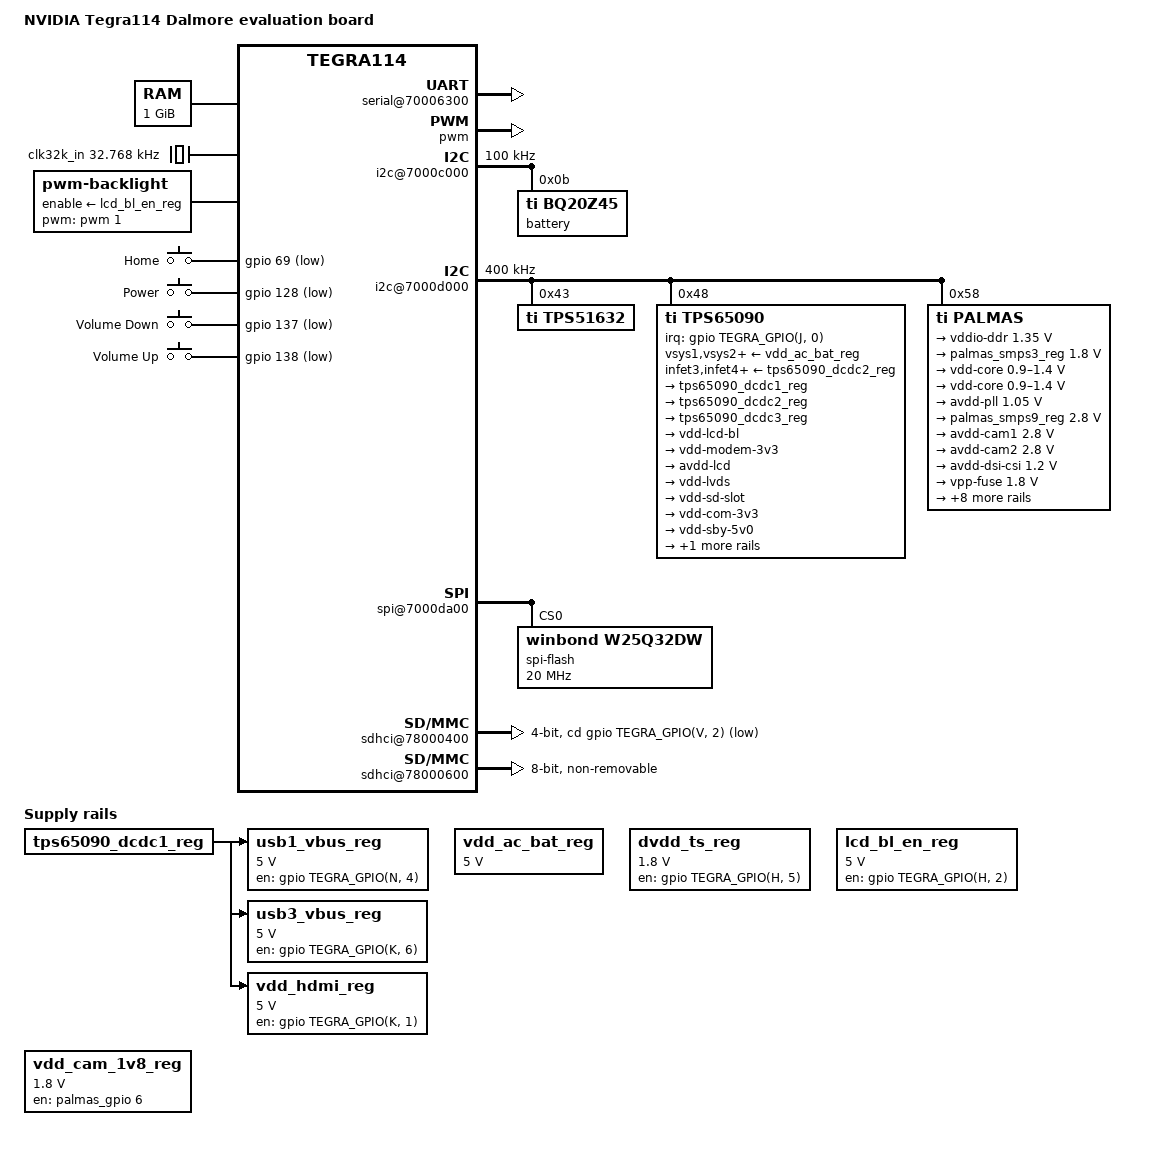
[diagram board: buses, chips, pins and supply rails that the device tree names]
/dts-v1/;

#include "tegra114.dtsi"

/ {
	model = "NVIDIA Tegra114 Dalmore evaluation board";
	compatible = "nvidia,dalmore", "nvidia,tegra114";

	memory {
		reg = <0x80000000 0x40000000>;
	};

	pinmux {
		pinctrl-names = "default";
		pinctrl-0 = <&state_default>;

		state_default: pinmux {
			clk1_out_pw4 {
				nvidia,pins = "clk1_out_pw4";
				nvidia,function = "extperiph1";
				nvidia,pull = <0>;
				nvidia,tristate = <0>;
				nvidia,enable-input = <0>;
			};
			dap1_din_pn1 {
				nvidia,pins = "dap1_din_pn1";
				nvidia,function = "i2s0";
				nvidia,pull = <0>;
				nvidia,tristate = <1>;
				nvidia,enable-input = <1>;
			};
			dap1_dout_pn2 {
				nvidia,pins = "dap1_dout_pn2",
						"dap1_fs_pn0",
						"dap1_sclk_pn3";
				nvidia,function = "i2s0";
				nvidia,pull = <0>;
				nvidia,tristate = <0>;
				nvidia,enable-input = <1>;
			};
			dap2_din_pa4 {
				nvidia,pins = "dap2_din_pa4";
				nvidia,function = "i2s1";
				nvidia,pull = <0>;
				nvidia,tristate = <1>;
				nvidia,enable-input = <1>;
			};
			dap2_dout_pa5 {
				nvidia,pins = "dap2_dout_pa5",
						"dap2_fs_pa2",
						"dap2_sclk_pa3";
				nvidia,function = "i2s1";
				nvidia,pull = <0>;
				nvidia,tristate = <0>;
				nvidia,enable-input = <1>;
			};
			dap4_din_pp5 {
				nvidia,pins = "dap4_din_pp5",
						"dap4_dout_pp6",
						"dap4_fs_pp4",
						"dap4_sclk_pp7";
				nvidia,function = "i2s3";
				nvidia,pull = <0>;
				nvidia,tristate = <0>;
				nvidia,enable-input = <1>;
			};
			dvfs_pwm_px0 {
				nvidia,pins = "dvfs_pwm_px0",
						"dvfs_clk_px2";
				nvidia,function = "cldvfs";
				nvidia,pull = <0>;
				nvidia,tristate = <0>;
				nvidia,enable-input = <0>;
			};
			ulpi_clk_py0 {
				nvidia,pins = "ulpi_clk_py0",
						"ulpi_data0_po1",
						"ulpi_data1_po2",
						"ulpi_data2_po3",
						"ulpi_data3_po4",
						"ulpi_data4_po5",
						"ulpi_data5_po6",
						"ulpi_data6_po7",
						"ulpi_data7_po0";
				nvidia,function = "ulpi";
				nvidia,pull = <0>;
				nvidia,tristate = <0>;
				nvidia,enable-input = <1>;
			};
			ulpi_dir_py1 {
				nvidia,pins = "ulpi_dir_py1",
						"ulpi_nxt_py2";
				nvidia,function = "ulpi";
				nvidia,pull = <0>;
				nvidia,tristate = <1>;
				nvidia,enable-input = <1>;
			};
			ulpi_stp_py3 {
				nvidia,pins = "ulpi_stp_py3";
				nvidia,function = "ulpi";
				nvidia,pull = <0>;
				nvidia,tristate = <0>;
				nvidia,enable-input = <0>;
			};
			cam_i2c_scl_pbb1 {
				nvidia,pins = "cam_i2c_scl_pbb1",
						"cam_i2c_sda_pbb2";
				nvidia,function = "i2c3";
				nvidia,pull = <0>;
				nvidia,tristate = <0>;
				nvidia,enable-input = <1>;
				nvidia,lock = <0>;
				nvidia,open-drain = <0>;
			};
			cam_mclk_pcc0 {
				nvidia,pins = "cam_mclk_pcc0",
						"pbb0";
				nvidia,function = "vi_alt3";
				nvidia,pull = <0>;
				nvidia,tristate = <0>;
				nvidia,enable-input = <0>;
				nvidia,lock = <0>;
			};
			gen2_i2c_scl_pt5 {
				nvidia,pins = "gen2_i2c_scl_pt5",
						"gen2_i2c_sda_pt6";
				nvidia,function = "i2c2";
				nvidia,pull = <0>;
				nvidia,tristate = <0>;
				nvidia,enable-input = <1>;
				nvidia,lock = <0>;
				nvidia,open-drain = <0>;
			};
			gmi_a16_pj7 {
				nvidia,pins = "gmi_a16_pj7";
				nvidia,function = "uartd";
				nvidia,pull = <0>;
				nvidia,tristate = <0>;
				nvidia,enable-input = <0>;
			};
			gmi_a17_pb0 {
				nvidia,pins = "gmi_a17_pb0",
						"gmi_a18_pb1";
				nvidia,function = "uartd";
				nvidia,pull = <0>;
				nvidia,tristate = <1>;
				nvidia,enable-input = <1>;
			};
			gmi_a19_pk7 {
				nvidia,pins = "gmi_a19_pk7";
				nvidia,function = "uartd";
				nvidia,pull = <0>;
				nvidia,tristate = <0>;
				nvidia,enable-input = <0>;
			};
			gmi_ad5_pg5 {
				nvidia,pins = "gmi_ad5_pg5",
						"gmi_cs6_n_pi3",
						"gmi_wr_n_pi0";
				nvidia,function = "spi4";
				nvidia,pull = <0>;
				nvidia,tristate = <0>;
				nvidia,enable-input = <1>;
			};
			gmi_ad6_pg6 {
				nvidia,pins = "gmi_ad6_pg6",
						"gmi_ad7_pg7";
				nvidia,function = "spi4";
				nvidia,pull = <2>;
				nvidia,tristate = <0>;
				nvidia,enable-input = <1>;
			};
			gmi_ad12_ph4 {
				nvidia,pins = "gmi_ad12_ph4";
				nvidia,function = "rsvd4";
				nvidia,pull = <0>;
				nvidia,tristate = <0>;
				nvidia,enable-input = <0>;
			};
			gmi_ad9_ph1 {
				nvidia,pins = "gmi_ad9_ph1";
				nvidia,function = "pwm1";
				nvidia,pull = <0>;
				nvidia,tristate = <0>;
				nvidia,enable-input = <0>;
			};
			gmi_cs1_n_pj2 {
				nvidia,pins = "gmi_cs1_n_pj2",
						"gmi_oe_n_pi1";
				nvidia,function = "soc";
				nvidia,pull = <0>;
				nvidia,tristate = <1>;
				nvidia,enable-input = <1>;
			};
			clk2_out_pw5 {
				nvidia,pins = "clk2_out_pw5";
				nvidia,function = "extperiph2";
				nvidia,pull = <0>;
				nvidia,tristate = <0>;
				nvidia,enable-input = <0>;
			};
			sdmmc1_clk_pz0 {
				nvidia,pins = "sdmmc1_clk_pz0";
				nvidia,function = "sdmmc1";
				nvidia,pull = <0>;
				nvidia,tristate = <0>;
				nvidia,enable-input = <1>;
			};
			sdmmc1_cmd_pz1 {
				nvidia,pins = "sdmmc1_cmd_pz1",
						"sdmmc1_dat0_py7",
						"sdmmc1_dat1_py6",
						"sdmmc1_dat2_py5",
						"sdmmc1_dat3_py4";
				nvidia,function = "sdmmc1";
				nvidia,pull = <2>;
				nvidia,tristate = <0>;
				nvidia,enable-input = <1>;
			};
			sdmmc1_wp_n_pv3 {
				nvidia,pins = "sdmmc1_wp_n_pv3";
				nvidia,function = "spi4";
				nvidia,pull = <2>;
				nvidia,tristate = <0>;
				nvidia,enable-input = <0>;
			};
			sdmmc3_clk_pa6 {
				nvidia,pins = "sdmmc3_clk_pa6";
				nvidia,function = "sdmmc3";
				nvidia,pull = <0>;
				nvidia,tristate = <0>;
				nvidia,enable-input = <1>;
			};
			sdmmc3_cmd_pa7 {
				nvidia,pins = "sdmmc3_cmd_pa7",
						"sdmmc3_dat0_pb7",
						"sdmmc3_dat1_pb6",
						"sdmmc3_dat2_pb5",
						"sdmmc3_dat3_pb4",
						"kb_col4_pq4",
						"sdmmc3_clk_lb_out_pee4",
						"sdmmc3_clk_lb_in_pee5";
				nvidia,function = "sdmmc3";
				nvidia,pull = <2>;
				nvidia,tristate = <0>;
				nvidia,enable-input = <1>;
			};
			sdmmc4_clk_pcc4 {
				nvidia,pins = "sdmmc4_clk_pcc4";
				nvidia,function = "sdmmc4";
				nvidia,pull = <0>;
				nvidia,tristate = <0>;
				nvidia,enable-input = <1>;
			};
			sdmmc4_cmd_pt7 {
				nvidia,pins = "sdmmc4_cmd_pt7",
						"sdmmc4_dat0_paa0",
						"sdmmc4_dat1_paa1",
						"sdmmc4_dat2_paa2",
						"sdmmc4_dat3_paa3",
						"sdmmc4_dat4_paa4",
						"sdmmc4_dat5_paa5",
						"sdmmc4_dat6_paa6",
						"sdmmc4_dat7_paa7";
				nvidia,function = "sdmmc4";
				nvidia,pull = <2>;
				nvidia,tristate = <0>;
				nvidia,enable-input = <1>;
			};
			clk_32k_out_pa0 {
				nvidia,pins = "clk_32k_out_pa0";
				nvidia,function = "blink";
				nvidia,pull = <0>;
				nvidia,tristate = <0>;
				nvidia,enable-input = <0>;
			};
			kb_col0_pq0 {
				nvidia,pins = "kb_col0_pq0",
						"kb_col1_pq1",
						"kb_col2_pq2",
						"kb_row0_pr0",
						"kb_row1_pr1",
						"kb_row2_pr2";
				nvidia,function = "kbc";
				nvidia,pull = <2>;
				nvidia,tristate = <0>;
				nvidia,enable-input = <1>;
			};
			dap3_din_pp1 {
				nvidia,pins = "dap3_din_pp1",
						"dap3_sclk_pp3";
				nvidia,function = "displayb";
				nvidia,pull = <0>;
				nvidia,tristate = <1>;
				nvidia,enable-input = <0>;
			};
			pv0 {
				nvidia,pins = "pv0";
				nvidia,function = "rsvd4";
				nvidia,pull = <0>;
				nvidia,tristate = <1>;
				nvidia,enable-input = <0>;
			};
			kb_row7_pr7 {
				nvidia,pins = "kb_row7_pr7";
				nvidia,function = "rsvd2";
				nvidia,pull = <2>;
				nvidia,tristate = <0>;
				nvidia,enable-input = <1>;
			};
			kb_row10_ps2 {
				nvidia,pins = "kb_row10_ps2";
				nvidia,function = "uarta";
				nvidia,pull = <0>;
				nvidia,tristate = <1>;
				nvidia,enable-input = <1>;
			};
			kb_row9_ps1 {
				nvidia,pins = "kb_row9_ps1";
				nvidia,function = "uarta";
				nvidia,pull = <0>;
				nvidia,tristate = <0>;
				nvidia,enable-input = <0>;
			};
			pwr_i2c_scl_pz6 {
				nvidia,pins = "pwr_i2c_scl_pz6",
						"pwr_i2c_sda_pz7";
				nvidia,function = "i2cpwr";
				nvidia,pull = <0>;
				nvidia,tristate = <0>;
				nvidia,enable-input = <1>;
				nvidia,lock = <0>;
				nvidia,open-drain = <0>;
			};
			sys_clk_req_pz5 {
				nvidia,pins = "sys_clk_req_pz5";
				nvidia,function = "sysclk";
				nvidia,pull = <0>;
				nvidia,tristate = <0>;
				nvidia,enable-input = <0>;
			};
			core_pwr_req {
				nvidia,pins = "core_pwr_req";
				nvidia,function = "pwron";
				nvidia,pull = <0>;
				nvidia,tristate = <0>;
				nvidia,enable-input = <0>;
			};
			cpu_pwr_req {
				nvidia,pins = "cpu_pwr_req";
				nvidia,function = "cpu";
				nvidia,pull = <0>;
				nvidia,tristate = <0>;
				nvidia,enable-input = <0>;
			};
			pwr_int_n {
				nvidia,pins = "pwr_int_n";
				nvidia,function = "pmi";
				nvidia,pull = <0>;
				nvidia,tristate = <1>;
				nvidia,enable-input = <1>;
			};
			reset_out_n {
				nvidia,pins = "reset_out_n";
				nvidia,function = "reset_out_n";
				nvidia,pull = <0>;
				nvidia,tristate = <0>;
				nvidia,enable-input = <0>;
			};
			clk3_out_pee0 {
				nvidia,pins = "clk3_out_pee0";
				nvidia,function = "extperiph3";
				nvidia,pull = <0>;
				nvidia,tristate = <0>;
				nvidia,enable-input = <0>;
			};
			gen1_i2c_scl_pc4 {
				nvidia,pins = "gen1_i2c_scl_pc4",
						"gen1_i2c_sda_pc5";
				nvidia,function = "i2c1";
				nvidia,pull = <0>;
				nvidia,tristate = <0>;
				nvidia,enable-input = <1>;
				nvidia,lock = <0>;
				nvidia,open-drain = <0>;
			};
			uart2_cts_n_pj5 {
				nvidia,pins = "uart2_cts_n_pj5";
				nvidia,function = "uartb";
				nvidia,pull = <0>;
				nvidia,tristate = <1>;
				nvidia,enable-input = <1>;
			};
			uart2_rts_n_pj6 {
				nvidia,pins = "uart2_rts_n_pj6";
				nvidia,function = "uartb";
				nvidia,pull = <0>;
				nvidia,tristate = <0>;
				nvidia,enable-input = <0>;
			};
			uart2_rxd_pc3 {
				nvidia,pins = "uart2_rxd_pc3";
				nvidia,function = "irda";
				nvidia,pull = <0>;
				nvidia,tristate = <1>;
				nvidia,enable-input = <1>;
			};
			uart2_txd_pc2 {
				nvidia,pins = "uart2_txd_pc2";
				nvidia,function = "irda";
				nvidia,pull = <0>;
				nvidia,tristate = <0>;
				nvidia,enable-input = <0>;
			};
			uart3_cts_n_pa1 {
				nvidia,pins = "uart3_cts_n_pa1",
						"uart3_rxd_pw7";
				nvidia,function = "uartc";
				nvidia,pull = <0>;
				nvidia,tristate = <1>;
				nvidia,enable-input = <1>;
			};
			uart3_rts_n_pc0 {
				nvidia,pins = "uart3_rts_n_pc0",
						"uart3_txd_pw6";
				nvidia,function = "uartc";
				nvidia,pull = <0>;
				nvidia,tristate = <0>;
				nvidia,enable-input = <0>;
			};
			owr {
				nvidia,pins = "owr";
				nvidia,function = "owr";
				nvidia,pull = <0>;
				nvidia,tristate = <0>;
				nvidia,enable-input = <1>;
			};
			hdmi_cec_pee3 {
				nvidia,pins = "hdmi_cec_pee3";
				nvidia,function = "cec";
				nvidia,pull = <0>;
				nvidia,tristate = <0>;
				nvidia,enable-input = <1>;
				nvidia,lock = <0>;
				nvidia,open-drain = <0>;
			};
			ddc_scl_pv4 {
				nvidia,pins = "ddc_scl_pv4",
						"ddc_sda_pv5";
				nvidia,function = "i2c4";
				nvidia,pull = <0>;
				nvidia,tristate = <0>;
				nvidia,enable-input = <1>;
				nvidia,lock = <0>;
				nvidia,rcv-sel = <1>;
			};
			spdif_in_pk6 {
				nvidia,pins = "spdif_in_pk6";
				nvidia,function = "usb";
				nvidia,pull = <2>;
				nvidia,tristate = <0>;
				nvidia,enable-input = <1>;
				nvidia,lock = <0>;
			};
			usb_vbus_en0_pn4 {
				nvidia,pins = "usb_vbus_en0_pn4";
				nvidia,function = "usb";
				nvidia,pull = <2>;
				nvidia,tristate = <0>;
				nvidia,enable-input = <1>;
				nvidia,lock = <0>;
				nvidia,open-drain = <1>;
			};
			gpio_x6_aud_px6 {
				nvidia,pins = "gpio_x6_aud_px6";
				nvidia,function = "spi6";
				nvidia,pull = <2>;
				nvidia,tristate = <1>;
				nvidia,enable-input = <1>;
			};
			gpio_x4_aud_px4 {
				nvidia,pins = "gpio_x4_aud_px4",
						"gpio_x7_aud_px7";
				nvidia,function = "rsvd1";
				nvidia,pull = <1>;
				nvidia,tristate = <0>;
				nvidia,enable-input = <0>;
			};
			gpio_x5_aud_px5 {
				nvidia,pins = "gpio_x5_aud_px5";
				nvidia,function = "rsvd1";
				nvidia,pull = <2>;
				nvidia,tristate = <0>;
				nvidia,enable-input = <1>;
			};
			gpio_w2_aud_pw2 {
				nvidia,pins = "gpio_w2_aud_pw2";
				nvidia,function = "rsvd2";
				nvidia,pull = <2>;
				nvidia,tristate = <0>;
				nvidia,enable-input = <1>;
			};
			gpio_w3_aud_pw3 {
				nvidia,pins = "gpio_w3_aud_pw3";
				nvidia,function = "spi6";
				nvidia,pull = <2>;
				nvidia,tristate = <0>;
				nvidia,enable-input = <1>;
			};
			gpio_x1_aud_px1 {
				nvidia,pins = "gpio_x1_aud_px1";
				nvidia,function = "rsvd4";
				nvidia,pull = <1>;
				nvidia,tristate = <0>;
				nvidia,enable-input = <1>;
			};
			gpio_x3_aud_px3 {
				nvidia,pins = "gpio_x3_aud_px3";
				nvidia,function = "rsvd4";
				nvidia,pull = <2>;
				nvidia,tristate = <0>;
				nvidia,enable-input = <1>;
			};
			dap3_fs_pp0 {
				nvidia,pins = "dap3_fs_pp0";
				nvidia,function = "i2s2";
				nvidia,pull = <1>;
				nvidia,tristate = <0>;
				nvidia,enable-input = <0>;
			};
			dap3_dout_pp2 {
				nvidia,pins = "dap3_dout_pp2";
				nvidia,function = "i2s2";
				nvidia,pull = <1>;
				nvidia,tristate = <0>;
				nvidia,enable-input = <0>;
			};
			pv1 {
				nvidia,pins = "pv1";
				nvidia,function = "rsvd1";
				nvidia,pull = <0>;
				nvidia,tristate = <0>;
				nvidia,enable-input = <1>;
			};
			pbb3 {
				nvidia,pins = "pbb3",
						"pbb5",
						"pbb6",
						"pbb7";
				nvidia,function = "rsvd4";
				nvidia,pull = <1>;
				nvidia,tristate = <0>;
				nvidia,enable-input = <0>;
			};
			pcc1 {
				nvidia,pins = "pcc1",
						"pcc2";
				nvidia,function = "rsvd4";
				nvidia,pull = <1>;
				nvidia,tristate = <0>;
				nvidia,enable-input = <1>;
			};
			gmi_ad0_pg0 {
				nvidia,pins = "gmi_ad0_pg0",
						"gmi_ad1_pg1";
				nvidia,function = "gmi";
				nvidia,pull = <0>;
				nvidia,tristate = <0>;
				nvidia,enable-input = <0>;
			};
			gmi_ad10_ph2 {
				nvidia,pins = "gmi_ad10_ph2",
						"gmi_ad11_ph3",
						"gmi_ad13_ph5",
						"gmi_ad8_ph0",
						"gmi_clk_pk1";
				nvidia,function = "gmi";
				nvidia,pull = <1>;
				nvidia,tristate = <0>;
				nvidia,enable-input = <0>;
			};
			gmi_ad2_pg2 {
				nvidia,pins = "gmi_ad2_pg2",
						"gmi_ad3_pg3";
				nvidia,function = "gmi";
				nvidia,pull = <0>;
				nvidia,tristate = <0>;
				nvidia,enable-input = <1>;
			};
			gmi_adv_n_pk0 {
				nvidia,pins = "gmi_adv_n_pk0",
						"gmi_cs0_n_pj0",
						"gmi_cs2_n_pk3",
						"gmi_cs4_n_pk2",
						"gmi_cs7_n_pi6",
						"gmi_dqs_p_pj3",
						"gmi_iordy_pi5",
						"gmi_wp_n_pc7";
				nvidia,function = "gmi";
				nvidia,pull = <2>;
				nvidia,tristate = <0>;
				nvidia,enable-input = <1>;
			};
			gmi_cs3_n_pk4 {
				nvidia,pins = "gmi_cs3_n_pk4";
				nvidia,function = "gmi";
				nvidia,pull = <2>;
				nvidia,tristate = <0>;
				nvidia,enable-input = <0>;
			};
			clk2_req_pcc5 {
				nvidia,pins = "clk2_req_pcc5";
				nvidia,function = "rsvd4";
				nvidia,pull = <0>;
				nvidia,tristate = <0>;
				nvidia,enable-input = <0>;
			};
			kb_col3_pq3 {
				nvidia,pins = "kb_col3_pq3",
						"kb_col6_pq6",
						"kb_col7_pq7";
				nvidia,function = "kbc";
				nvidia,pull = <2>;
				nvidia,tristate = <0>;
				nvidia,enable-input = <0>;
			};
			kb_col5_pq5 {
				nvidia,pins = "kb_col5_pq5";
				nvidia,function = "kbc";
				nvidia,pull = <2>;
				nvidia,tristate = <0>;
				nvidia,enable-input = <1>;
			};
			kb_row3_pr3 {
				nvidia,pins = "kb_row3_pr3",
						"kb_row4_pr4",
						"kb_row6_pr6",
						"kb_row8_ps0";
				nvidia,function = "kbc";
				nvidia,pull = <1>;
				nvidia,tristate = <0>;
				nvidia,enable-input = <1>;
			};
			clk3_req_pee1 {
				nvidia,pins = "clk3_req_pee1";
				nvidia,function = "rsvd4";
				nvidia,pull = <0>;
				nvidia,tristate = <0>;
				nvidia,enable-input = <0>;
			};
			pu4 {
				nvidia,pins = "pu4";
				nvidia,function = "displayb";
				nvidia,pull = <0>;
				nvidia,tristate = <0>;
				nvidia,enable-input = <0>;
			};
			pu5 {
				nvidia,pins = "pu5",
						"pu6";
				nvidia,function = "displayb";
				nvidia,pull = <0>;
				nvidia,tristate = <0>;
				nvidia,enable-input = <1>;
			};
			hdmi_int_pn7 {
				nvidia,pins = "hdmi_int_pn7";
				nvidia,function = "rsvd1";
				nvidia,pull = <1>;
				nvidia,tristate = <0>;
				nvidia,enable-input = <1>;
			};
			clk1_req_pee2 {
				nvidia,pins = "clk1_req_pee2",
						"usb_vbus_en1_pn5";
				nvidia,function = "rsvd4";
				nvidia,pull = <1>;
				nvidia,tristate = <1>;
				nvidia,enable-input = <0>;
			};

			drive_sdio1 {
				nvidia,pins = "drive_sdio1";
				nvidia,high-speed-mode = <1>;
				nvidia,schmitt = <0>;
				nvidia,low-power-mode = <3>;
				nvidia,pull-down-strength = <36>;
				nvidia,pull-up-strength = <20>;
				nvidia,slew-rate-rising = <2>;
				nvidia,slew-rate-falling = <2>;
			};
			drive_sdio3 {
				nvidia,pins = "drive_sdio3";
				nvidia,high-speed-mode = <1>;
				nvidia,schmitt = <0>;
				nvidia,low-power-mode = <3>;
				nvidia,pull-down-strength = <22>;
				nvidia,pull-up-strength = <36>;
				nvidia,slew-rate-rising = <0>;
				nvidia,slew-rate-falling = <0>;
			};
			drive_gma {
				nvidia,pins = "drive_gma";
				nvidia,high-speed-mode = <1>;
				nvidia,schmitt = <0>;
				nvidia,low-power-mode = <3>;
				nvidia,pull-down-strength = <2>;
				nvidia,pull-up-strength = <1>;
				nvidia,slew-rate-rising = <0>;
				nvidia,slew-rate-falling = <0>;
				nvidia,drive-type = <1>;
			};
		};
	};

	serial@70006300 {
		status = "okay";
	};

	pwm {
		status = "okay";
	};

	i2c@7000c000 {
		status = "okay";
		clock-frequency = <100000>;

		battery: smart-battery {
			compatible = "ti,bq20z45", "sbs,sbs-battery";
			reg = <0xb>;
			battery-name = "battery";
			sbs,i2c-retry-count = <2>;
			sbs,poll-retry-count = <100>;
		};
	};

	i2c@7000d000 {
		status = "okay";
		clock-frequency = <400000>;

		tps51632 {
			compatible = "ti,tps51632";
			reg = <0x43>;
			regulator-name = "vdd-cpu";
			regulator-min-microvolt = <500000>;
			regulator-max-microvolt = <1520000>;
			regulator-boot-on;
			regulator-always-on;
		};

		tps65090 {
			compatible = "ti,tps65090";
			reg = <0x48>;
			interrupt-parent = <&gpio>;
			interrupts = <TEGRA_GPIO(J, 0) IRQ_TYPE_LEVEL_HIGH>;

			vsys1-supply = <&vdd_ac_bat_reg>;
			vsys2-supply = <&vdd_ac_bat_reg>;
			vsys3-supply = <&vdd_ac_bat_reg>;
			infet1-supply = <&vdd_ac_bat_reg>;
			infet2-supply = <&vdd_ac_bat_reg>;
			infet3-supply = <&tps65090_dcdc2_reg>;
			infet4-supply = <&tps65090_dcdc2_reg>;
			infet5-supply = <&tps65090_dcdc2_reg>;
			infet6-supply = <&tps65090_dcdc2_reg>;
			infet7-supply = <&tps65090_dcdc2_reg>;
			vsys-l1-supply = <&vdd_ac_bat_reg>;
			vsys-l2-supply = <&vdd_ac_bat_reg>;

			charger {
				compatible = "ti,tps65090-charger";
				ti,enable-low-current-chrg;
			};

			regulators {
				tps65090_dcdc1_reg: dcdc1 {
					regulator-name = "vdd-sys-5v0";
					regulator-always-on;
					regulator-boot-on;
				};

				tps65090_dcdc2_reg: dcdc2 {
					regulator-name = "vdd-sys-3v3";
					regulator-always-on;
					regulator-boot-on;
				};

				tps65090_dcdc3_reg: dcdc3 {
					regulator-name = "vdd-ao";
					regulator-always-on;
					regulator-boot-on;
				};

				fet1 {
					regulator-name = "vdd-lcd-bl";
				};

				fet3 {
					regulator-name = "vdd-modem-3v3";
				};

				fet4 {
					regulator-name = "avdd-lcd";
				};

				fet5 {
					regulator-name = "vdd-lvds";
				};

				fet6 {
					regulator-name = "vdd-sd-slot";
					regulator-always-on;
					regulator-boot-on;
				};

				fet7 {
					regulator-name = "vdd-com-3v3";
				};

				ldo1 {
					regulator-name = "vdd-sby-5v0";
					regulator-always-on;
					regulator-boot-on;
				};

				ldo2 {
					regulator-name = "vdd-sby-3v3";
					regulator-always-on;
					regulator-boot-on;
				};
			};
		};

		palmas: tps65913 {
			compatible = "ti,palmas";
			reg = <0x58>;
			interrupts = <0 86 0x8>;

			#interrupt-cells = <2>;
			interrupt-controller;

			palmas_gpio: gpio {
				compatible = "ti,palmas-gpio";
				gpio-controller;
				#gpio-cells = <2>;
			};

			pmic {
				compatible = "ti,tps65913-pmic", "ti,palmas-pmic";
				smps1-in-supply = <&tps65090_dcdc3_reg>;
				smps3-in-supply = <&tps65090_dcdc3_reg>;
				smps4-in-supply = <&tps65090_dcdc2_reg>;
				smps7-in-supply = <&tps65090_dcdc2_reg>;
				smps8-in-supply = <&tps65090_dcdc2_reg>;
				smps9-in-supply = <&tps65090_dcdc2_reg>;
				ldo1-in-supply = <&tps65090_dcdc2_reg>;
				ldo2-in-supply = <&tps65090_dcdc2_reg>;
				ldo3-in-supply = <&palmas_smps3_reg>;
				ldo4-in-supply = <&tps65090_dcdc2_reg>;
				ldo5-in-supply = <&vdd_ac_bat_reg>;
				ldo6-in-supply = <&tps65090_dcdc2_reg>;
				ldo7-in-supply = <&tps65090_dcdc2_reg>;
				ldo8-in-supply = <&tps65090_dcdc3_reg>;
				ldo9-in-supply = <&palmas_smps9_reg>;
				ldoln-in-supply = <&tps65090_dcdc1_reg>;
				ldousb-in-supply = <&tps65090_dcdc1_reg>;

				regulators {
					smps12 {
						regulator-name = "vddio-ddr";
						regulator-min-microvolt = <1350000>;
						regulator-max-microvolt = <1350000>;
						regulator-always-on;
						regulator-boot-on;
					};

					palmas_smps3_reg: smps3 {
						regulator-name = "vddio-1v8";
						regulator-min-microvolt = <1800000>;
						regulator-max-microvolt = <1800000>;
						regulator-always-on;
						regulator-boot-on;
					};

					smps45 {
						regulator-name = "vdd-core";
						regulator-min-microvolt = <900000>;
						regulator-max-microvolt = <1400000>;
						regulator-always-on;
						regulator-boot-on;
					};

					smps457 {
						regulator-name = "vdd-core";
						regulator-min-microvolt = <900000>;
						regulator-max-microvolt = <1400000>;
						regulator-always-on;
						regulator-boot-on;
					};

					smps8 {
						regulator-name = "avdd-pll";
						regulator-min-microvolt = <1050000>;
						regulator-max-microvolt = <1050000>;
						regulator-always-on;
						regulator-boot-on;
					};

					palmas_smps9_reg: smps9 {
						regulator-name = "sdhci-vdd-sd-slot";
						regulator-min-microvolt = <2800000>;
						regulator-max-microvolt = <2800000>;
						regulator-always-on;
					};

					ldo1 {
						regulator-name = "avdd-cam1";
						regulator-min-microvolt = <2800000>;
						regulator-max-microvolt = <2800000>;
					};

					ldo2 {
						regulator-name = "avdd-cam2";
						regulator-min-microvolt = <2800000>;
						regulator-max-microvolt = <2800000>;
					};

					ldo3 {
						regulator-name = "avdd-dsi-csi";
						regulator-min-microvolt = <1200000>;
						regulator-max-microvolt = <1200000>;
						regulator-always-on;
						regulator-boot-on;
					};

					ldo4 {
						regulator-name = "vpp-fuse";
						regulator-min-microvolt = <1800000>;
						regulator-max-microvolt = <1800000>;
					};

					ldo6 {
						regulator-name = "vdd-sensor-2v85";
						regulator-min-microvolt = <2850000>;
						regulator-max-microvolt = <2850000>;
					};

					ldo7 {
						regulator-name = "vdd-af-cam1";
						regulator-min-microvolt = <2800000>;
						regulator-max-microvolt = <2800000>;
					};

					ldo8 {
						regulator-name = "vdd-rtc";
						regulator-min-microvolt = <900000>;
						regulator-max-microvolt = <900000>;
						regulator-always-on;
						regulator-boot-on;
						ti,enable-ldo8-tracking;
					};

					ldo9 {
						regulator-name = "vddio-sdmmc-2";
						regulator-min-microvolt = <1800000>;
						regulator-max-microvolt = <3300000>;
						regulator-always-on;
						regulator-boot-on;
					};

					ldoln {
						regulator-name = "hvdd-usb";
						regulator-min-microvolt = <3300000>;
						regulator-max-microvolt = <3300000>;
					};

					ldousb {
						regulator-name = "avdd-usb";
						regulator-min-microvolt = <3300000>;
						regulator-max-microvolt = <3300000>;
						regulator-always-on;
						regulator-boot-on;
					};

					regen1 {
						regulator-name = "rail-3v3";
						regulator-max-microvolt = <3300000>;
						regulator-always-on;
						regulator-boot-on;
					};

					regen2 {
						regulator-name = "rail-5v0";
						regulator-max-microvolt = <5000000>;
						regulator-always-on;
						regulator-boot-on;
					};
				};
			};

			rtc {
				compatible = "ti,palmas-rtc";
				interrupt-parent = <&palmas>;
				interrupts = <8 0>;
			};
		};
	};

	spi@7000da00 {
		status = "okay";
		spi-max-frequency = <25000000>;
		spi-flash@0 {
			compatible = "winbond,w25q32dw";
			reg = <0>;
			spi-max-frequency = <20000000>;
		};
	};

	pmc {
		nvidia,invert-interrupt;
		nvidia,suspend-mode = <1>;
		nvidia,cpu-pwr-good-time = <500>;
		nvidia,cpu-pwr-off-time = <300>;
		nvidia,core-pwr-good-time = <641 3845>;
		nvidia,core-pwr-off-time = <61036>;
		nvidia,core-power-req-active-high;
		nvidia,sys-clock-req-active-high;
	};

	sdhci@78000400 {
		cd-gpios = <&gpio TEGRA_GPIO(V, 2) GPIO_ACTIVE_LOW>;
		bus-width = <4>;
		status = "okay";
	};

	sdhci@78000600 {
		bus-width = <8>;
		status = "okay";
		non-removable;
	};

	clocks {
		compatible = "simple-bus";
		#address-cells = <1>;
		#size-cells = <0>;

		clk32k_in: clock {
			compatible = "fixed-clock";
			reg=<0>;
			#clock-cells = <0>;
			clock-frequency = <32768>;
		};
	};

	memory-controller@7001b000 {
		nvidia,use-chip-sku;
		chip-sku@34 {
			nvidia,chip-sku = <3 4>;
			emc-table@12750 {
				compatible = "nvidia,tegra11-emc-table";
				clock-frequency = <12750>;
				nvidia,revision = <0x41>;
				nvidia,src-sel-reg = <0x4000003e>;
				nvidia,emc-min-mv = <900>;
				nvidia,burst-regs-num = <99>;
				nvidia,emc-trimmers-num = <30>;
				nvidia,burst-up-down-regs-num = <11>;
				nvidia,emc-registers = <0x00000000 0x00000003
					0x00000000 0x00000000 0x00000000 0x00000004
					0x0000000a 0x00000003 0x0000000b 0x00000000
					0x00000000 0x00000003 0x00000001 0x00000000
					0x00000005 0x00000005 0x00000006 0x00010000
					0x00000000 0x00000004 0x0000000d 0x00000060
					0x00000000 0x00000018 0x00000002 0x00000002
					0x00000001 0x00000000 0x00000007 0x0000000f
					0x00000005 0x00000005 0x00000004 0x00000004
					0x00000004 0x00000001 0x00000000 0x00000004
					0x00000005 0x00000064 0x00000006 0x00000020
					0x00000000 0x0000aa88 0x002c00a0 0x00008000
					0x0006c000 0x0006c000 0x0006c000 0x0006c000
					0x00000000 0x00000000 0x00000000 0x00000000
					0x00000000 0x00000000 0x00000000 0x00000000
					0x001112a0 0x00000000 0x0000a11c 0x00000000
					0x77ffc085 0x81f1f108 0x03035504 0x0000003f
					0x0000003f 0x00000000 0x02000000 0x00000802
					0x00000000 0x00000042 0x000c000c 0x000c000c
					0x00000000 0x00000000 0x00000000 0x00000000
					0x800001c6 0x1f7df7df 0x0000001f 0x40040001
					0x8000003f 0x00000001 0x00000001 0x00000002
					0x00000000 0x00000001 0x00000001 0x00000002
					0x00000008 0x00000002 0x00000001 0x00000003
					0x00000006 0x06030102 0x000a0402 0x77e30303
					0x001f0000>;
				nvidia,emc-trimmers-0 = <0x00000000 0x00000004
					0x00000007 0x00000004 0x00000004 0x0006c000
					0x00000009 0x00000000 0x0000000d 0x00208208
					0x20820800 0x00048000 0xa0f10000 0x00000000
					0x00000000 0x00000000 0x00000000 0x00000000
					0x0006c000 0x0006c000 0x0006c000 0x00048000
					0x00048000 0x00048000 0x00000000 0x00000000
					0x00000000 0x00000000 0x00000000 0x00000000>;
				nvidia,emc-trimmers-1 = <0x00000000 0x00000004
					0x00000007 0x00000004 0x00000004 0x0006c000
					0x00000009 0x00000000 0x0000000d 0x00208208
					0x20820800 0x00048000 0xa8f10000 0x00000000
					0x00000000 0x00000000 0x00000000 0x00000000
					0x0006c000 0x0006c000 0x0006c000 0x00048000
					0x00048000 0x00048000 0x00000000 0x00000000
					0x00000000 0x00000000 0x00000000 0x00000000>;
				nvidia,emc-burst-up-down-regs = <0x0000000e 0x00ff00ff
					0x00ff00ff 0x00ff00ff 0x000000ff 0x00ff00ff
					0x00ff00ff 0x000000ff 0x00ff00ff 0x00ff00ff
					0x00ff00ff>;
				nvidia,emc-zcal-cnt-long = <0x00000042>;
				nvidia,emc-acal-interval = <0x001fffff>;
				nvidia,emc-cfg = <0x7320000e>;
				nvidia,emc-mode-reset = <0x80001221>;
				nvidia,emc-mode-1 = <0x80100003>;
				nvidia,emc-mode-2 = <0x80200008>;
				nvidia,emc-mode-4 = <0x00000000>;
				nvidia,emc-clock-latency-change = <57820>;
			};
			emc-table@20400 {
				compatible = "nvidia,tegra11-emc-table";
				clock-frequency = <20400>;
				nvidia,revision = <0x41>;
				nvidia,src-sel-reg = <0x40000026>;
				nvidia,emc-min-mv = <900>;
				nvidia,burst-regs-num = <99>;
				nvidia,emc-trimmers-num = <30>;
				nvidia,burst-up-down-regs-num = <11>;
				nvidia,emc-registers = <0x00000000 0x00000005
					0x00000000 0x00000000 0x00000000 0x00000004
					0x0000000a 0x00000003 0x0000000b 0x00000000
					0x00000000 0x00000003 0x00000001 0x00000000
					0x00000005 0x00000005 0x00000006 0x00010000
					0x00000000 0x00000004 0x0000000d 0x0000009a
					0x00000000 0x00000026 0x00000002 0x00000002
					0x00000001 0x00000000 0x00000007 0x0000000f
					0x00000006 0x00000006 0x00000004 0x00000004
					0x00000004 0x00000001 0x00000000 0x00000004
					0x00000005 0x000000a0 0x00000006 0x00000020
					0x00000000 0x0000aa88 0x002c00a0 0x00008000
					0x0006c000 0x0006c000 0x0006c000 0x0006c000
					0x00000000 0x00000000 0x00000000 0x00000000
					0x00000000 0x00000000 0x00000000 0x00000000
					0x001112a0 0x00000000 0x0000a11c 0x00000000
					0x77ffc085 0x81f1f108 0x03035504 0x0000003f
					0x0000003f 0x00000000 0x02000000 0x00000802
					0x00000000 0x00000042 0x000c000c 0x000c000c
					0x00000000 0x00000000 0x00000000 0x00000000
					0x8000023a 0x1f7df7df 0x0000001f 0x40020001
					0x80000046 0x00000001 0x00000001 0x00000002
					0x00000000 0x00000001 0x00000001 0x00000002
					0x00000008 0x00000002 0x00000001 0x00000003
					0x00000006 0x06030102 0x000a0402 0x76230303
					0x001f0000>;
				nvidia,emc-trimmers-0 = <0x00000000 0x00000004
					0x00000007 0x00000004 0x00000004 0x0006c000
					0x00000009 0x00000000 0x0000000d 0x00208208
					0x20820800 0x00048000 0xa0f10000 0x00000000
					0x00000000 0x00000000 0x00000000 0x00000000
					0x0006c000 0x0006c000 0x0006c000 0x00048000
					0x00048000 0x00048000 0x00000000 0x00000000
					0x00000000 0x00000000 0x00000000 0x00000000>;
				nvidia,emc-trimmers-1 = <0x00000000 0x00000004
					0x00000007 0x00000004 0x00000004 0x0006c000
					0x00000009 0x00000000 0x0000000d 0x00208208
					0x20820800 0x00048000 0xa8f10000 0x00000000
					0x00000000 0x00000000 0x00000000 0x00000000
					0x0006c000 0x0006c000 0x0006c000 0x00048000
					0x00048000 0x00048000 0x00000000 0x00000000
					0x00000000 0x00000000 0x00000000 0x00000000>;
				nvidia,emc-burst-up-down-regs = <0x00000014 0x00ff00ff
					0x00ff00ff 0x00ff00ff 0x000000ff 0x00ff00ff
					0x00ff00ff 0x000000ff 0x00ff00ff 0x00ff00ff
					0x00ff00ff>;
				nvidia,emc-zcal-cnt-long = <0x00000042>;
				nvidia,emc-acal-interval = <0x001fffff>;
				nvidia,emc-cfg = <0x7320000e>;
				nvidia,emc-mode-reset = <0x80001221>;
				nvidia,emc-mode-1 = <0x80100003>;
				nvidia,emc-mode-2 = <0x80200008>;
				nvidia,emc-mode-4 = <0x00000000>;
				nvidia,emc-clock-latency-change = <35610>;
			};
			emc-table@40800 {
				compatible = "nvidia,tegra11-emc-table";
				clock-frequency = <40800>;
				nvidia,revision = <0x41>;
				nvidia,src-sel-reg = <0x40000012>;
				nvidia,emc-min-mv = <900>;
				nvidia,burst-regs-num = <99>;
				nvidia,emc-trimmers-num = <30>;
				nvidia,burst-up-down-regs-num = <11>;
				nvidia,emc-registers = <0x00000001 0x0000000a
					0x00000000 0x00000001 0x00000000 0x00000004
					0x0000000a 0x00000003 0x0000000b 0x00000000
					0x00000000 0x00000003 0x00000001 0x00000000
					0x00000005 0x00000005 0x00000006 0x00010000
					0x00000000 0x00000004 0x0000000d 0x00000134
					0x00000000 0x0000004d 0x00000002 0x00000002
					0x00000001 0x00000000 0x00000008 0x0000000f
					0x0000000c 0x0000000c 0x00000004 0x00000004
					0x00000004 0x00000002 0x00000000 0x00000004
					0x00000005 0x0000013f 0x00000006 0x00000020
					0x00000000 0x0000aa88 0x002c00a0 0x00008000
					0x0006c000 0x0006c000 0x0006c000 0x0006c000
					0x00000000 0x00000000 0x00000000 0x00000000
					0x00000000 0x00000000 0x00000000 0x00000000
					0x001112a0 0x00000000 0x0000a11c 0x00000000
					0x77ffc085 0x81f1f108 0x03035504 0x0000003f
					0x0000003f 0x00000000 0x02000000 0x00000802
					0x00000000 0x00000042 0x000c000c 0x000c000c
					0x00000000 0x00000000 0x00000000 0x00000000
					0x80000370 0x1f7df7df 0x0000001f 0xa0000001
					0x8000005b 0x00000001 0x00000001 0x00000002
					0x00000000 0x00000001 0x00000001 0x00000002
					0x00000008 0x00000002 0x00000001 0x00000003
					0x00000006 0x06030102 0x000a0402 0x74a30303
					0x001f0000>;
				nvidia,emc-trimmers-0 = <0x00000000 0x00000004
					0x00000007 0x00000004 0x00000004 0x0006c000
					0x00000009 0x00000000 0x0000000d 0x00208208
					0x20820800 0x00048000 0xa0f10000 0x00000000
					0x00000000 0x00000000 0x00000000 0x00000000
					0x0006c000 0x0006c000 0x0006c000 0x00048000
					0x00048000 0x00048000 0x00000000 0x00000000
					0x00000000 0x00000000 0x00000000 0x00000000>;
				nvidia,emc-trimmers-1 = <0x00000000 0x00000004
					0x00000007 0x00000004 0x00000004 0x0006c000
					0x00000009 0x00000000 0x0000000d 0x00208208
					0x20820800 0x00048000 0xa8f10000 0x00000000
					0x00000000 0x00000000 0x00000000 0x00000000
					0x0006c000 0x0006c000 0x0006c000 0x00048000
					0x00048000 0x00048000 0x00000000 0x00000000
					0x00000000 0x00000000 0x00000000 0x00000000>;
				nvidia,emc-burst-up-down-regs = <0x0000002a 0x00b000b0
					0x00b000c4 0x00d700eb 0x000000eb 0x00eb00eb
					0x00ff00eb 0x000000ff 0x00ff00ff 0x00ff00ff
					0x00ff00ff>;
				nvidia,emc-zcal-cnt-long = <0x00000042>;
				nvidia,emc-acal-interval = <0x001fffff>;
				nvidia,emc-cfg = <0x7320000e>;
				nvidia,emc-mode-reset = <0x80001221>;
				nvidia,emc-mode-1 = <0x80100003>;
				nvidia,emc-mode-2 = <0x80200008>;
				nvidia,emc-mode-4 = <0x00000000>;
				nvidia,emc-clock-latency-change = <20850>;
			};
			emc-table@68000 {
				compatible = "nvidia,tegra11-emc-table";
				clock-frequency = <68000>;
				nvidia,revision = <0x41>;
				nvidia,src-sel-reg = <0x4000000a>;
				nvidia,emc-min-mv = <900>;
				nvidia,burst-regs-num = <99>;
				nvidia,emc-trimmers-num = <30>;
				nvidia,burst-up-down-regs-num = <11>;
				nvidia,emc-registers = <0x00000003 0x00000011
					0x00000000 0x00000002 0x00000000 0x00000004
					0x0000000a 0x00000003 0x0000000b 0x00000000
					0x00000000 0x00000003 0x00000001 0x00000000
					0x00000005 0x00000005 0x00000006 0x00010000
					0x00000000 0x00000004 0x0000000d 0x00000202
					0x00000000 0x00000080 0x00000002 0x00000002
					0x00000001 0x00000000 0x0000000f 0x0000000f
					0x00000013 0x00000013 0x00000004 0x00000004
					0x00000004 0x00000003 0x00000000 0x00000004
					0x00000005 0x00000213 0x00000006 0x00000020
					0x00000000 0x0000aa88 0x002c00a0 0x00008000
					0x0006c000 0x0006c000 0x0006c000 0x0006c000
					0x00000000 0x00000000 0x00000000 0x00000000
					0x00000000 0x00000000 0x00000000 0x00000000
					0x001112a0 0x00000000 0x0000a11c 0x00000000
					0x77ffc085 0x81f1f108 0x03035504 0x0000003f
					0x0000003f 0x00000000 0x02000000 0x00000802
					0x00000000 0x00000042 0x000c000c 0x000c000c
					0x00000000 0x00000000 0x00000000 0x00000000
					0x8000050e 0x1f7df7df 0x0000001f 0x00000001
					0x80000076 0x00000001 0x00000001 0x00000002
					0x00000000 0x00000001 0x00000001 0x00000002
					0x00000008 0x00000002 0x00000001 0x00000003
					0x00000006 0x06030102 0x000a0402 0x74230403
					0x001f0000>;
				nvidia,emc-trimmers-0 = <0x00000000 0x00000004
					0x00000007 0x00000004 0x00000004 0x0006c000
					0x00000009 0x00000000 0x0000000d 0x00208208
					0x20820800 0x00048000 0xa0f10000 0x00000000
					0x00000000 0x00000000 0x00000000 0x00000000
					0x0006c000 0x0006c000 0x0006c000 0x00048000
					0x00048000 0x00048000 0x00000000 0x00000000
					0x00000000 0x00000000 0x00000000 0x00000000>;
				nvidia,emc-trimmers-1 = <0x00000000 0x00000004
					0x00000007 0x00000004 0x00000004 0x0006c000
					0x00000009 0x00000000 0x0000000d 0x00208208
					0x20820800 0x00048000 0xa8f10000 0x00000000
					0x00000000 0x00000000 0x00000000 0x00000000
					0x0006c000 0x0006c000 0x0006c000 0x00048000
					0x00048000 0x00048000 0x00000000 0x00000000
					0x00000000 0x00000000 0x00000000 0x00000000>;
				nvidia,emc-burst-up-down-regs = <0x00000046 0x00690069
					0x00690075 0x0081008d 0x0000008d 0x008d008d
					0x00bc008d 0x000000bc 0x00bc00bc 0x00ff00ff
					0x00ff00ff>;
				nvidia,emc-zcal-cnt-long = <0x00000042>;
				nvidia,emc-acal-interval = <0x001fffff>;
				nvidia,emc-cfg = <0x7320000e>;
				nvidia,emc-mode-reset = <0x80001221>;
				nvidia,emc-mode-1 = <0x80100003>;
				nvidia,emc-mode-2 = <0x80200008>;
				nvidia,emc-mode-4 = <0x00000000>;
				nvidia,emc-clock-latency-change = <10720>;
			};
			emc-table@102000 {
				compatible = "nvidia,tegra11-emc-table";
				clock-frequency = <102000>;
				nvidia,revision = <0x41>;
				nvidia,src-sel-reg = <0x40000006>;
				nvidia,emc-min-mv = <900>;
				nvidia,burst-regs-num = <99>;
				nvidia,emc-trimmers-num = <30>;
				nvidia,burst-up-down-regs-num = <11>;
				nvidia,emc-registers = <0x00000004 0x0000001a
					0x00000000 0x00000003 0x00000001 0x00000004
					0x0000000a 0x00000003 0x0000000b 0x00000001
					0x00000001 0x00000003 0x00000001 0x00000000
					0x00000005 0x00000005 0x00000006 0x00010000
					0x00000000 0x00000004 0x0000000d 0x00000303
					0x00000000 0x000000c0 0x00000002 0x00000002
					0x00000001 0x00000000 0x00000018 0x0000000f
					0x0000001c 0x0000001c 0x00000004 0x00000004
					0x00000004 0x00000005 0x00000000 0x00000004
					0x00000005 0x0000031c 0x00000006 0x00000020
					0x00000000 0x0000aa88 0x002c00a0 0x00008000
					0x0006c000 0x0006c000 0x0006c000 0x0006c000
					0x00000000 0x00000000 0x00000000 0x00000000
					0x00000000 0x00000000 0x00000000 0x00000000
					0x001112a0 0x00000000 0x0000a11c 0x00000000
					0x77ffc085 0x81f1f108 0x03035504 0x0000003f
					0x0000003f 0x00000000 0x02000000 0x00000802
					0x00000000 0x00000042 0x000c000c 0x000c000c
					0x00000000 0x00000000 0x00000000 0x00000000
					0x80000714 0x1f7df7df 0x0000001f 0x08000001
					0x80000098 0x00000001 0x00000001 0x00000003
					0x00000000 0x00000002 0x00000001 0x00000002
					0x00000008 0x00000002 0x00000001 0x00000003
					0x00000006 0x06030102 0x000a0403 0x73c30504
					0x001f0000>;
				nvidia,emc-trimmers-0 = <0x00000000 0x00000004
					0x00000007 0x00000004 0x00000004 0x0006c000
					0x00000009 0x00000000 0x0000000d 0x00208208
					0x20820800 0x00048000 0xa0f10000 0x00000000
					0x00000000 0x00000000 0x00000000 0x00000000
					0x0006c000 0x0006c000 0x0006c000 0x00048000
					0x00048000 0x00048000 0x00000000 0x00000000
					0x00000000 0x00000000 0x00000000 0x00000000>;
				nvidia,emc-trimmers-1 = <0x00000000 0x00000004
					0x00000007 0x00000004 0x00000004 0x0006c000
					0x00000009 0x00000000 0x0000000d 0x00208208
					0x20820800 0x00048000 0xa8f10000 0x00000000
					0x00000000 0x00000000 0x00000000 0x00000000
					0x0006c000 0x0006c000 0x0006c000 0x00048000
					0x00048000 0x00048000 0x00000000 0x00000000
					0x00000000 0x00000000 0x00000000 0x00000000>;
				nvidia,emc-burst-up-down-regs = <0x00000068 0x00460046
					0x0046004e 0x0056005e 0x0000005e 0x005e005e
					0x007d005e 0x0000007d 0x007d007d 0x00ff00ff
					0x00ff00ff>;
				nvidia,emc-zcal-cnt-long = <0x00000042>;
				nvidia,emc-acal-interval = <0x001fffff>;
				nvidia,emc-cfg = <0x7320000e>;
				nvidia,emc-mode-reset = <0x80001221>;
				nvidia,emc-mode-1 = <0x80100003>;
				nvidia,emc-mode-2 = <0x80200008>;
				nvidia,emc-mode-4 = <0x00000000>;
				nvidia,emc-clock-latency-change = <6890>;
			};
			emc-table@204000 {
				compatible = "nvidia,tegra11-emc-table";
				clock-frequency = <204000>;
				nvidia,revision = <0x41>;
				nvidia,src-sel-reg = <0x40000002>;
				nvidia,emc-min-mv = <900>;
				nvidia,burst-regs-num = <99>;
				nvidia,emc-trimmers-num = <30>;
				nvidia,burst-up-down-regs-num = <11>;
				nvidia,emc-registers = <0x00000009 0x00000035
					0x00000000 0x00000007 0x00000002 0x00000004
					0x0000000a 0x00000003 0x0000000b 0x00000002
					0x00000002 0x00000003 0x00000001 0x00000000
					0x00000005 0x00000005 0x00000006 0x00010000
					0x00000000 0x00000004 0x0000000d 0x00000607
					0x00000000 0x00000181 0x00000002 0x00000002
					0x00000001 0x00000000 0x00000032 0x0000000f
					0x00000038 0x00000038 0x00000004 0x00000004
					0x00000004 0x00000009 0x00000000 0x00000004
					0x00000005 0x00000638 0x00000006 0x00000020
					0x00000000 0x0000aa88 0x000000a0 0x00008000
					0x0006c000 0x0006c000 0x0006c000 0x0006c000
					0x00000000 0x00000000 0x00000000 0x00000000
					0x00000000 0x00000000 0x00000000 0x00000000
					0x001112a0 0x00000000 0x0000a11c 0x00000000
					0x77ffc085 0x81f1f108 0x05057404 0x0000003f
					0x0000003f 0x00000000 0x02000000 0x00000802
					0x00020000 0x00000100 0x000c000c 0x000c000c
					0x00000000 0x00000000 0x00000000 0x00000000
					0x80000d22 0x1f7df7df 0x0000001f 0x01000003
					0x800000fe 0x00000001 0x00000001 0x00000005
					0x00000002 0x00000004 0x00000001 0x00000002
					0x00000008 0x00000002 0x00000001 0x00000003
					0x00000006 0x06030102 0x000a0405 0x73840a06
					0x001f0000>;
				nvidia,emc-trimmers-0 = <0x00000000 0x00000004
					0x00000007 0x00000004 0x00000004 0x0006c000
					0x00000009 0x00000000 0x0000000d 0x0079e79e
					0x20820800 0x00048000 0xa0f10000 0x00000000
					0x00000808 0x00000000 0x00000000 0x00000000
					0x0006c000 0x0006c000 0x0006c000 0x00048000
					0x00048000 0x00048000 0x00000000 0x00000000
					0x00000000 0x00000000 0x00000000 0x00000000>;
				nvidia,emc-trimmers-1 = <0x00000000 0x00000004
					0x00000007 0x00000004 0x00000004 0x0006c000
					0x00000009 0x00000000 0x0000000d 0x0079e79e
					0x20820800 0x00048000 0xa8f10000 0x00000000
					0x00000808 0x00000000 0x00000000 0x00000000
					0x0006c000 0x0006c000 0x0006c000 0x00048000
					0x00048000 0x00048000 0x00000000 0x00000000
					0x00000000 0x00000000 0x00000000 0x00000000>;
				nvidia,emc-burst-up-down-regs = <0x000000d0 0x00230023
					0x00230027 0x002b002f 0x0000002f 0x002f002f
					0x003e002f 0x0000003e 0x003e003e 0x00ff00c8
					0x00ff00ff>;
				nvidia,emc-zcal-cnt-long = <0x00000042>;
				nvidia,emc-acal-interval = <0x001fffff>;
				nvidia,emc-cfg = <0x7320000e>;
				nvidia,emc-mode-reset = <0x80001221>;
				nvidia,emc-mode-1 = <0x80100003>;
				nvidia,emc-mode-2 = <0x80200008>;
				nvidia,emc-mode-4 = <0x00000000>;
				nvidia,emc-clock-latency-change = <3420>;
			};
			emc-table@312000 {
				compatible = "nvidia,tegra11-emc-table";
				clock-frequency = <312000>;
				nvidia,revision = <0x41>;
				nvidia,src-sel-reg = <0x24000002>;
				nvidia,emc-min-mv = <1000>;
				nvidia,burst-regs-num = <99>;
				nvidia,emc-trimmers-num = <30>;
				nvidia,burst-up-down-regs-num = <11>;
				nvidia,emc-registers = <0x0000000e 0x00000050
					0x00000000 0x00000009 0x00000003 0x00000004
					0x00000008 0x00000002 0x00000009 0x00000003
					0x00000003 0x00000002 0x00000001 0x00000000
					0x00000004 0x00000004 0x00000007 0x00080006
					0x00000000 0x00000004 0x0000000d 0x00000945
					0x00000000 0x00000251 0x00000001 0x00000008
					0x00000001 0x00000000 0x0000004d 0x0000000e
					0x00000055 0x00000200 0x00000004 0x00000004
					0x00000004 0x0000000d 0x00000000 0x00000004
					0x00000005 0x00000986 0x00000006 0x00000020
					0x00000000 0x0000ba88 0x002c00a0 0x00008000
					0x00030000 0x00030000 0x00030000 0x00030000
					0x00028000 0x00028000 0x00028000 0x00028000
					0x00000000 0x00000000 0x00000000 0x00000000
					0x001112a0 0x00000000 0x0001013d 0x00000000
					0x77ffc085 0x81f1f108 0x03035504 0x00000000
					0x0000003f 0x00000000 0x02000000 0x00000802
					0x00020000 0x00000100 0x0171000c 0x0171000c
					0x00000000 0x00000000 0x00000000 0x00000000
					0x80001395 0x1f7df7df 0x0000001f 0x0b000004
					0x8000016a 0x00000001 0x00000002 0x00000007
					0x00000004 0x00000006 0x00000001 0x00000002
					0x00000007 0x00000002 0x00000002 0x00000004
					0x00000006 0x06040202 0x000b0607 0x76e50f08
					0x001f0000>;
				nvidia,emc-trimmers-0 = <0x00000000 0x00000006
					0x00000007 0x00000005 0x00000004 0x00030000
					0x0000000b 0x00028000 0x0000000d 0x00208208
					0x10410400 0x00030000 0xa0f10000 0x00014000
					0x00000000 0x00000000 0x00000000 0x00014000
					0x00030000 0x00030000 0x00030000 0x00030000
					0x00030000 0x00030000 0x00000000 0x00000000
					0x00000000 0x00028000 0x00028000 0x00028000>;
				nvidia,emc-trimmers-1 = <0x00000000 0x00000006
					0x00000007 0x00000005 0x00000004 0x00030000
					0x0000000b 0x00028000 0x0000000d 0x00208208
					0x10410400 0x00030000 0xa8f10000 0x00014000
					0x00000000 0x00000000 0x00000000 0x00014000
					0x00030000 0x00030000 0x00030000 0x00030000
					0x00030000 0x00030000 0x00000000 0x00000000
					0x00000000 0x00028000 0x00028000 0x00028000>;
				nvidia,emc-burst-up-down-regs = <0x00000140 0x00170017
					0x00170019 0x001c001e 0x0000001e 0x001e001e
					0x0029001e 0x00000029 0x00290029 0x00ff0082
					0x00ff00ff>;
				nvidia,emc-zcal-cnt-long = <0x00000042>;
				nvidia,emc-acal-interval = <0x001fffff>;
				nvidia,emc-cfg = <0x5320000e>;
				nvidia,emc-mode-reset = <0x80000321>;
				nvidia,emc-mode-1 = <0x80100002>;
				nvidia,emc-mode-2 = <0x80200000>;
				nvidia,emc-mode-4 = <0x00000000>;
				nvidia,emc-clock-latency-change = <2680>;
			};
			emc-table@408000 {
				compatible = "nvidia,tegra11-emc-table";
				clock-frequency = <408000>;
				nvidia,revision = <0x41>;
				nvidia,src-sel-reg = <0x40000000>;
				nvidia,emc-min-mv = <1000>;
				nvidia,burst-regs-num = <99>;
				nvidia,emc-trimmers-num = <30>;
				nvidia,burst-up-down-regs-num = <11>;
				nvidia,emc-registers = <0x00000012 0x00000069
					0x00000000 0x0000000d 0x00000004 0x00000005
					0x00000009 0x00000002 0x0000000c 0x00000004
					0x00000004 0x00000002 0x00000001 0x00000000
					0x00000004 0x00000004 0x00000007 0x00080006
					0x00000000 0x00000004 0x0000000e 0x00000c2f
					0x00000000 0x0000030b 0x00000001 0x00000008
					0x00000001 0x00000000 0x00000066 0x00000011
					0x0000006f 0x00000200 0x00000004 0x00000004
					0x00000004 0x00000011 0x00000000 0x00000004
					0x00000005 0x00000c70 0x00000006 0x00000020
					0x00000000 0x0000ba88 0x002c0080 0x00008000
					0x00028000 0x00028000 0x00028000 0x00028000
					0x00000000 0x00000000 0x00000000 0x00000000
					0x00000000 0x00000000 0x00000000 0x00000000
					0x001112a0 0x00000000 0x0001013d 0x00000000
					0x77ffc085 0x81f1f108 0x03035504 0x00000000
					0x0000003f 0x00000000 0x02000000 0x00000802
					0x00020000 0x00000100 0x0158000c 0x0158000c
					0x00000000 0x00000000 0x00000000 0x00000000
					0x80001944 0x1f7df7df 0x0000001f 0x02000006
					0x80000190 0x00000001 0x00000002 0x0000000a
					0x00000006 0x00000008 0x00000001 0x00000002
					0x00000009 0x00000002 0x00000002 0x00000004
					0x00000006 0x06040202 0x000e070a 0x7547130b
					0x001f0000>;
				nvidia,emc-trimmers-0 = <0x00000000 0x00000006
					0x00000007 0x00000005 0x00000004 0x00028000
					0x0000000c 0x00000000 0x0000000e 0x00208208
					0x10410400 0x00030000 0xa0f10000 0x00014000
					0x00000000 0x00000000 0x00000000 0x00014000
					0x00028000 0x00028000 0x00028000 0x00030000
					0x00030000 0x00030000 0x00000000 0x00000000
					0x00000000 0x00000000 0x00000000 0x00000000>;
				nvidia,emc-trimmers-1 = <0x00000000 0x00000006
					0x00000007 0x00000005 0x00000004 0x00028000
					0x0000000c 0x00000000 0x0000000e 0x00208208
					0x10410400 0x00030000 0xa8f10000 0x00014000
					0x00000000 0x00000000 0x00000000 0x00014000
					0x00028000 0x00028000 0x00028000 0x00030000
					0x00030000 0x00030000 0x00000000 0x00000000
					0x00000000 0x00000000 0x00000000 0x00000000>;
				nvidia,emc-burst-up-down-regs = <0x000000d1 0x00110011
					0x00110013 0x00150017 0x00000017 0x00170017
					0x001f0017 0x0000001f 0x001f001f 0x00d30064
					0x00d300d3>;
				nvidia,emc-zcal-cnt-long = <0x00000042>;
				nvidia,emc-acal-interval = <0x001fffff>;
				nvidia,emc-cfg = <0x53200006>;
				nvidia,emc-mode-reset = <0x80000731>;
				nvidia,emc-mode-1 = <0x80100002>;
				nvidia,emc-mode-2 = <0x80200008>;
				nvidia,emc-mode-4 = <0x00000000>;
				nvidia,emc-clock-latency-change = <1750>;
			};
			emc-table@624000 {
				compatible = "nvidia,tegra11-emc-table";
				clock-frequency = <624000>;
				nvidia,revision = <0x41>;
				nvidia,src-sel-reg = <0x24000000>;
				nvidia,emc-min-mv = <1100>;
				nvidia,burst-regs-num = <99>;
				nvidia,emc-trimmers-num = <30>;
				nvidia,burst-up-down-regs-num = <11>;
				nvidia,emc-registers = <0x0000001d 0x000000a1
					0x00000000 0x00000014 0x00000007 0x00000007
					0x0000000b 0x00000003 0x00000010 0x00000007
					0x00000007 0x00000002 0x00000001 0x00000000
					0x00000005 0x00000005 0x0000000b 0x000c000a
					0x00000000 0x00000007 0x00000012 0x000012c4
					0x00000000 0x000004b1 0x00000002 0x0000000d
					0x00000001 0x00000000 0x0000009c 0x00000015
					0x000000a9 0x00000200 0x00000005 0x00000005
					0x00000005 0x00000019 0x00000000 0x00000006
					0x00000007 0x00001305 0x0000000a 0x00000020
					0x00000000 0x0000ba88 0xf00d0191 0x00008000
					0x007fc00a 0x007fc00a 0x007fc00a 0x007fc00a
					0x00000000 0x00000000 0x00000000 0x00000000
					0x00000000 0x00000000 0x00000000 0x00000000
					0x001112a0 0x00000000 0x0000013d 0x00000000
					0x77ffc085 0x81f1f108 0x07077504 0x00000000
					0x0000003f 0x00000000 0x02000000 0x00000802
					0x00020000 0x00000100 0x0122000c 0x0122000c
					0x00000000 0x00000000 0x00000000 0x00000000
					0x8000261a 0x1f7df7df 0x0000001f 0x06000009
					0x80000190 0x00000003 0x00000004 0x0000000f
					0x00000009 0x0000000c 0x00000001 0x00000003
					0x0000000b 0x00000002 0x00000002 0x00000005
					0x00000007 0x07050202 0x00130b0f 0x736a1d10
					0x001f0000>;
				nvidia,emc-trimmers-0 = <0x00000000 0x00000004
					0x0000000b 0x00000008 0x00000004 0x007fc00a
					0x0000000c 0x00000000 0x00000012 0x0028a28a
					0x10410400 0x00000009 0xa0f10000 0x00000000
					0x00000909 0x00000000 0x00000000 0x00000000
					0x007fc00a 0x007fc00a 0x007fc00a 0x00000009
					0x00000009 0x00000009 0x00000000 0x00000000
					0x00000000 0x00000000 0x00000000 0x00000000>;
				nvidia,emc-trimmers-1 = <0x00000000 0x00000004
					0x0000000b 0x00000008 0x00000004 0x007fc00a
					0x0000000c 0x00000000 0x00000012 0x0028a28a
					0x10410400 0x00000009 0xa8f10000 0x00000000
					0x00000909 0x00000000 0x00000000 0x00000000
					0x007fc00a 0x007fc00a 0x007fc00a 0x00000009
					0x00000009 0x00000009 0x00000000 0x00000000
					0x00000000 0x00000000 0x00000000 0x00000000>;
				nvidia,emc-burst-up-down-regs = <0x0000013f 0x000b000b
					0x000b000c 0x000e000f 0x0000000f 0x000f000f
					0x0014000f 0x00000014 0x00140014 0x008a0041
					0x008a008a>;
				nvidia,emc-zcal-cnt-long = <0x00000042>;
				nvidia,emc-acal-interval = <0x001fffff>;
				nvidia,emc-cfg = <0x53200000>;
				nvidia,emc-mode-reset = <0x80000b61>;
				nvidia,emc-mode-1 = <0x80100002>;
				nvidia,emc-mode-2 = <0x80200010>;
				nvidia,emc-mode-4 = <0x00000000>;
				nvidia,emc-clock-latency-change = <1440>;
			};
			emc-table@792000 {
				compatible = "nvidia,tegra11-emc-table";
				clock-frequency = <792000>;
				nvidia,revision = <0x41>;
				nvidia,src-sel-reg = <0x80000000>;
				nvidia,emc-min-mv = <1100>;
				nvidia,burst-regs-num = <99>;
				nvidia,emc-trimmers-num = <30>;
				nvidia,burst-up-down-regs-num = <11>;
				nvidia,emc-registers = <0x00000024 0x000000cd
					0x00000000 0x00000019 0x0000000a 0x00000009
					0x0000000d 0x00000004 0x00000013 0x0000000a
					0x0000000a 0x00000003 0x00000001 0x00000000
					0x00000006 0x00000006 0x0000000b 0x000d000a
					0x00000000 0x00000008 0x00000014 0x000017e4
					0x00000000 0x000005f9 0x00000003 0x00000012
					0x00000001 0x00000000 0x000000c6 0x00000018
					0x000000d6 0x00000200 0x00000005 0x00000005
					0x00000005 0x00000020 0x00000000 0x00000007
					0x00000008 0x00001825 0x0000000a 0x80000020
					0x00000000 0x0000ba88 0xf0070191 0x00008000
					0x00000008 0x00000008 0x00000008 0x00000008
					0x00000000 0x00000000 0x00000000 0x00000000
					0x00000000 0x00000000 0x00000000 0x00000000
					0x001112a0 0x00000000 0x0000013d 0x00000000
					0x77ffc085 0x81f1f508 0x07076604 0x00000000
					0x0000003f 0x00000000 0x02000000 0x00000802
					0x00020000 0x00000100 0x00f8000f 0x00f8000f
					0x00000000 0x00000000 0x00000000 0x00000000
					0x80003018 0x1f7df7df 0x0000001f 0x0e00000b
					0x80000190 0x00000004 0x00000005 0x00000013
					0x0000000c 0x0000000f 0x00000002 0x00000003
					0x0000000c 0x00000002 0x00000002 0x00000006
					0x00000008 0x08060202 0x00170e13 0x734c2414
					0x001f0000>;
				nvidia,emc-trimmers-0 = <0x00000000 0x00000006
					0x0000000b 0x00000008 0x00000006 0x00000008
					0x0000000d 0x00000000 0x00000014 0x00249249
					0x10410400 0x0000000a 0xa0f10f0f 0x00000008
					0x00000b0b 0x00000000 0x00000000 0x00000000
					0x00000008 0x00000008 0x00000008 0x0000000a
					0x0000000a 0x0000000a 0x00000000 0x00000000
					0x00000000 0x00000000 0x00000000 0x00000000>;
				nvidia,emc-trimmers-1 = <0x00000000 0x00000006
					0x0000000b 0x00000008 0x00000006 0x00000008
					0x0000000d 0x00000000 0x00000014 0x00249249
					0x10410400 0x0000000a 0xa8f10f0f 0x00000008
					0x00000b0b 0x00000000 0x00000000 0x00000000
					0x00000008 0x00000008 0x00000008 0x0000000a
					0x0000000a 0x0000000a 0x00000000 0x00000000
					0x00000000 0x00000000 0x00000000 0x00000000>;
				nvidia,emc-burst-up-down-regs = <0x00000196 0x00090009
					0x0009000a 0x000b000c 0x0000000c 0x000c000c
					0x0010000c 0x00000010 0x00100010 0x006d0033
					0x006d006d>;
				nvidia,emc-zcal-cnt-long = <0x00000042>;
				nvidia,emc-acal-interval = <0x001fffff>;
				nvidia,emc-cfg = <0x53200000>;
				nvidia,emc-mode-reset = <0x80000d71>;
				nvidia,emc-mode-1 = <0x80100002>;
				nvidia,emc-mode-2 = <0x80200418>;
				nvidia,emc-mode-4 = <0x00000000>;
				nvidia,emc-clock-latency-change = <1200>;
			};
			emc-table@924000 {
				compatible = "nvidia,tegra11-emc-table";
				clock-frequency = <924000>;
				nvidia,revision = <0x41>;
				nvidia,src-sel-reg = <0x80000000>;
				nvidia,emc-min-mv = <1170>;
				nvidia,burst-regs-num = <99>;
				nvidia,emc-trimmers-num = <30>;
				nvidia,burst-up-down-regs-num = <11>;
				nvidia,emc-registers = <0x0000002b 0x000000f1
					0x00000000 0x0000001e 0x0000000b 0x00000009
					0x0000000f 0x00000005 0x00000018 0x0000000b
					0x0000000b 0x00000004 0x00000001 0x00000000
					0x00000007 0x00000007 0x0000000d 0x000f000c
					0x00000000 0x0000000a 0x00000016 0x00001c39
					0x00000000 0x0000070e 0x00000004 0x00000015
					0x00000001 0x00000000 0x000000e8 0x0000001d
					0x000000fd 0x00000200 0x00000006 0x00000006
					0x00000006 0x00000026 0x00000000 0x00000009
					0x0000000a 0x00001c7a 0x00000000 0x80000020
					0x00000000 0x00005088 0xf0030191 0x00008000
					0x00000007 0x00000007 0x00000007 0x00000007
					0x0002800c 0x0002800c 0x0002800c 0x0002800c
					0x00000000 0x00000000 0x00000000 0x00000000
					0x001112a0 0x00000000 0x0000013d 0x00000000
					0x77ffc085 0x81f1f508 0x07077504 0x00000000
					0x0000003f 0x00000000 0x02000000 0x00000801
					0x00020000 0x00000128 0x00cb000f 0x00cb000f
					0x00000000 0x00000000 0x00000004 0x00000004
					0x8000388a 0x1f7df7df 0x0000001f 0x0000000e
					0x80000190 0x00000005 0x00000006 0x00000016
					0x0000000e 0x00000012 0x00000002 0x00000004
					0x0000000f 0x00000002 0x00000002 0x00000006
					0x00000009 0x09060202 0x001b1016 0x734f2b17
					0x001f0000>;
				nvidia,emc-trimmers-0 = <0x00000000 0x00000006
					0x0000000c 0x0000000a 0x00000006 0x00000007
					0x0000000d 0x0002800c 0x00000016 0x00249249
					0x10410400 0x00004007 0xa0f10f0f 0x00000008
					0x00000f0f 0x00000000 0x00000000 0x00000000
					0x00000007 0x00000007 0x00000007 0x00004007
					0x00004007 0x00004007 0x00000000 0x00000000
					0x00000000 0x0002800c 0x0002800c 0x0002800c>;
				nvidia,emc-trimmers-1 = <0x00000000 0x00000006
					0x0000000c 0x0000000a 0x00000006 0x00000007
					0x0000000d 0x0002800c 0x00000016 0x00249249
					0x10410400 0x00004007 0xa8f10f0f 0x00000008
					0x00000b0b 0x00000000 0x00000000 0x00000000
					0x00000007 0x00000007 0x00000007 0x00004007
					0x00004007 0x00004007 0x00000000 0x00000000
					0x00000000 0x0002800c 0x0002800c 0x0002800c>;
				nvidia,emc-burst-up-down-regs = <0x000001d9 0x00070007
					0x00070008 0x0009000a 0x0000000a 0x000a000a
					0x000d000a 0x0000000d 0x000d000d 0x005d002c
					0x005d005d>;
				nvidia,emc-zcal-cnt-long = <0x0000004d>;
				nvidia,emc-acal-interval = <0x001fffff>;
				nvidia,emc-cfg = <0x53000000>;
				nvidia,emc-mode-reset = <0x80000115>;
				nvidia,emc-mode-1 = <0x80100002>;
				nvidia,emc-mode-2 = <0x80200420>;
				nvidia,emc-mode-4 = <0x00000000>;
				nvidia,emc-clock-latency-change = <1180>;
			};
		};
		chip-sku@5 {
			nvidia,chip-sku = <5>;
			emc-table@12750 {
				compatible = "nvidia,tegra11-emc-table";
				clock-frequency = <12750>;
				nvidia,revision = <0x41>;
				nvidia,src-sel-reg = <0x4000003e>;
				nvidia,emc-min-mv = <900>;
				nvidia,burst-regs-num = <99>;
				nvidia,emc-trimmers-num = <30>;
				nvidia,burst-up-down-regs-num = <11>;
				nvidia,emc-registers = <0x00000000 0x00000003
					0x00000000 0x00000000 0x00000000 0x00000004
					0x0000000a 0x00000003 0x0000000b 0x00000000
					0x00000000 0x00000003 0x00000001 0x00000000
					0x00000005 0x00000005 0x00000006 0x00010000
					0x00000000 0x00000004 0x0000000d 0x00000060
					0x00000000 0x00000018 0x00000002 0x00000002
					0x00000001 0x00000000 0x00000007 0x0000000f
					0x00000005 0x00000005 0x00000004 0x00000004
					0x00000004 0x00000001 0x00000000 0x00000004
					0x00000005 0x00000064 0x00000006 0x00000020
					0x00000000 0x0000aa88 0x002c00a0 0x00008000
					0x0006c000 0x0006c000 0x0006c000 0x0006c000
					0x00000000 0x00000000 0x00000000 0x00000000
					0x00000000 0x00000000 0x00000000 0x00000000
					0x001112a0 0x00000000 0x0000a11c 0x00000000
					0x77ffc085 0x81f1f108 0x03035504 0x00000000
					0x0000003f 0x00000000 0x02000000 0x00000802
					0x00000000 0x00000042 0x000c000c 0x000c000c
					0x00000000 0x00000000 0x00000000 0x00000000
					0x800001c6 0x1f7df7df 0x0000001f 0x40040001
					0x8000003f 0x00000001 0x00000001 0x00000002
					0x00000000 0x00000001 0x00000001 0x00000002
					0x00000008 0x00000002 0x00000001 0x00000003
					0x00000006 0x06030102 0x000a0402 0x77e30303
					0x001f0000>;
				nvidia,emc-trimmers-0 = <0x00000000 0x00000004
					0x00000007 0x00000004 0x00000004 0x0006c000
					0x00000009 0x00000000 0x0000000d 0x00208208
					0x20820800 0x00048000 0xa0f10000 0x00000000
					0x00000000 0x00000000 0x00000000 0x00000000
					0x0006c000 0x0006c000 0x0006c000 0x00048000
					0x00048000 0x00048000 0x00000000 0x00000000
					0x00000000 0x00000000 0x00000000 0x00000000>;
				nvidia,emc-trimmers-1 = <0x00000000 0x00000004
					0x00000007 0x00000004 0x00000004 0x0006c000
					0x00000009 0x00000000 0x0000000d 0x00208208
					0x20820800 0x00048000 0xa8f10000 0x00000000
					0x00000000 0x00000000 0x00000000 0x00000000
					0x0006c000 0x0006c000 0x0006c000 0x00048000
					0x00048000 0x00048000 0x00000000 0x00000000
					0x00000000 0x00000000 0x00000000 0x00000000 >;
				nvidia,emc-burst-up-down-regs = <0x0000000e 0x00ff00ff
					0x00ff00ff 0x00ff00ff 0x000000ff 0x00ff00ff
					0x00ff00ff 0x000000ff 0x00ff00ff 0x00ff00ff
					0x00ff00ff>;
				nvidia,emc-zcal-cnt-long = <0x00000042>;
				nvidia,emc-acal-interval = <0x001fffff>;
				nvidia,emc-cfg = <0x7320000e>;
				nvidia,emc-mode-reset = <0x80001221>;
				nvidia,emc-mode-1 = <0x80100003>;
				nvidia,emc-mode-2 = <0x80200008>;
				nvidia,emc-mode-4 = <0x00000000>;
				nvidia,emc-clock-latency-change = <57820>;
			};
			emc-table@20400 {
				compatible = "nvidia,tegra11-emc-table";
				clock-frequency = <20400>;
				nvidia,revision = <0x41>;
				nvidia,src-sel-reg = <0x40000026>;
				nvidia,emc-min-mv = <900>;
				nvidia,burst-regs-num = <99>;
				nvidia,emc-trimmers-num = <30>;
				nvidia,burst-up-down-regs-num = <11>;
				nvidia,emc-registers = <0x00000000 0x00000005
					0x00000000 0x00000000 0x00000000 0x00000004
					0x0000000a 0x00000003 0x0000000b 0x00000000
					0x00000000 0x00000003 0x00000001 0x00000000
					0x00000005 0x00000005 0x00000006 0x00010000
					0x00000000 0x00000004 0x0000000d 0x0000009a
					0x00000000 0x00000026 0x00000002 0x00000002
					0x00000001 0x00000000 0x00000007 0x0000000f
					0x00000006 0x00000006 0x00000004 0x00000004
					0x00000004 0x00000001 0x00000000 0x00000004
					0x00000005 0x000000a0 0x00000006 0x00000020
					0x00000000 0x0000aa88 0x002c00a0 0x00008000
					0x0006c000 0x0006c000 0x0006c000 0x0006c000
					0x00000000 0x00000000 0x00000000 0x00000000
					0x00000000 0x00000000 0x00000000 0x00000000
					0x001112a0 0x00000000 0x0000a11c 0x00000000
					0x77ffc085 0x81f1f108 0x03035504 0x00000000
					0x0000003f 0x00000000 0x02000000 0x00000802
					0x00000000 0x00000042 0x000c000c 0x000c000c
					0x00000000 0x00000000 0x00000000 0x00000000
					0x8000023a 0x1f7df7df 0x0000001f 0x40020001
					0x80000046 0x00000001 0x00000001 0x00000002
					0x00000000 0x00000001 0x00000001 0x00000002
					0x00000008 0x00000002 0x00000001 0x00000003
					0x00000006 0x06030102 0x000a0402 0x76230303
					0x001f0000>;
				nvidia,emc-trimmers-0 = <0x00000000 0x00000004
					0x00000007 0x00000004 0x00000004 0x0006c000
					0x00000009 0x00000000 0x0000000d 0x00208208
					0x20820800 0x00048000 0xa0f10000 0x00000000
					0x00000000 0x00000000 0x00000000 0x00000000
					0x0006c000 0x0006c000 0x0006c000 0x00048000
					0x00048000 0x00048000 0x00000000 0x00000000
					0x00000000 0x00000000 0x00000000 0x00000000>;
				nvidia,emc-trimmers-1 = <0x00000000 0x00000004
					0x00000007 0x00000004 0x00000004 0x0006c000
					0x00000009 0x00000000 0x0000000d 0x00208208
					0x20820800 0x00048000 0xa8f10000 0x00000000
					0x00000000 0x00000000 0x00000000 0x00000000
					0x0006c000 0x0006c000 0x0006c000 0x00048000
					0x00048000 0x00048000 0x00000000 0x00000000
					0x00000000 0x00000000 0x00000000 0x00000000>;
				nvidia,emc-burst-up-down-regs = <0x00000014 0x00ff00ff
					0x00ff00ff 0x00ff00ff 0x000000ff 0x00ff00ff
					0x00ff00ff 0x000000ff 0x00ff00ff 0x00ff00ff
					0x00ff00ff>;
				nvidia,emc-zcal-cnt-long = <0x00000042>;
				nvidia,emc-acal-interval = <0x001fffff>;
				nvidia,emc-cfg = <0x7320000e>;
				nvidia,emc-mode-reset = <0x80001221>;
				nvidia,emc-mode-1 = <0x80100003>;
				nvidia,emc-mode-2 = <0x80200008>;
				nvidia,emc-mode-4 = <0x00000000>;
				nvidia,emc-clock-latency-change = <35610>;
			};
			emc-table@40800 {
				compatible = "nvidia,tegra11-emc-table";
				clock-frequency = <40800>;
				nvidia,revision = <0x41>;
				nvidia,src-sel-reg = <0x40000012>;
				nvidia,emc-min-mv = <900>;
				nvidia,burst-regs-num = <99>;
				nvidia,emc-trimmers-num = <30>;
				nvidia,burst-up-down-regs-num = <11>;
				nvidia,emc-registers = <0x00000001 0x0000000a
					0x00000000 0x00000001 0x00000000 0x00000004
					0x0000000a 0x00000003 0x0000000b 0x00000000
					0x00000000 0x00000003 0x00000001 0x00000000
					0x00000005 0x00000005 0x00000006 0x00010000
					0x00000000 0x00000004 0x0000000d 0x00000134
					0x00000000 0x0000004d 0x00000002 0x00000002
					0x00000001 0x00000000 0x00000008 0x0000000f
					0x0000000c 0x0000000c 0x00000004 0x00000004
					0x00000004 0x00000002 0x00000000 0x00000004
					0x00000005 0x0000013f 0x00000006 0x00000020
					0x00000000 0x0000aa88 0x002c00a0 0x00008000
					0x0006c000 0x0006c000 0x0006c000 0x0006c000
					0x00000000 0x00000000 0x00000000 0x00000000
					0x00000000 0x00000000 0x00000000 0x00000000
					0x001112a0 0x00000000 0x0000a11c 0x00000000
					0x77ffc085 0x81f1f108 0x03035504 0x00000000
					0x0000003f 0x00000000 0x02000000 0x00000802
					0x00000000 0x00000042 0x000c000c 0x000c000c
					0x00000000 0x00000000 0x00000000 0x00000000
					0x80000370 0x1f7df7df 0x0000001f 0xa0000001
					0x8000005b 0x00000001 0x00000001 0x00000002
					0x00000000 0x00000001 0x00000001 0x00000002
					0x00000008 0x00000002 0x00000001 0x00000003
					0x00000006 0x06030102 0x000a0402 0x74a30303
					0x001f0000>;
				nvidia,emc-trimmers-0 = <0x00000000 0x00000004
					0x00000007 0x00000004 0x00000004 0x0006c000
					0x00000009 0x00000000 0x0000000d 0x00208208
					0x20820800 0x00048000 0xa0f10000 0x00000000
					0x00000000 0x00000000 0x00000000 0x00000000
					0x0006c000 0x0006c000 0x0006c000 0x00048000
					0x00048000 0x00048000 0x00000000 0x00000000
					0x00000000 0x00000000 0x00000000 0x00000000>;
				nvidia,emc-trimmers-1 = <0x00000000 0x00000004
					0x00000007 0x00000004 0x00000004 0x0006c000
					0x00000009 0x00000000 0x0000000d 0x00208208
					0x20820800 0x00048000 0xa8f10000 0x00000000
					0x00000000 0x00000000 0x00000000 0x00000000
					0x0006c000 0x0006c000 0x0006c000 0x00048000
					0x00048000 0x00048000 0x00000000 0x00000000
					0x00000000 0x00000000 0x00000000 0x00000000>;
				nvidia,emc-burst-up-down-regs = <0x0000002a 0x00b000b0
					0x00b000c4 0x00d700eb 0x000000eb 0x00eb00eb
					0x00ff00eb 0x000000ff 0x00ff00ff 0x00ff00ff
					0x00ff00ff>;
				nvidia,emc-zcal-cnt-long = <0x00000042>;
				nvidia,emc-acal-interval = <0x001fffff>;
				nvidia,emc-cfg = <0x7320000e>;
				nvidia,emc-mode-reset = <0x80001221>;
				nvidia,emc-mode-1 = <0x80100003>;
				nvidia,emc-mode-2 = <0x80200008>;
				nvidia,emc-mode-4 = <0x00000000>;
				nvidia,emc-clock-latency-change = <20850>;
			};
			emc-table@68000 {
				compatible = "nvidia,tegra11-emc-table";
				clock-frequency = <68000>;
				nvidia,revision = <0x41>;
				nvidia,src-sel-reg = <0x4000000a>;
				nvidia,emc-min-mv = <900>;
				nvidia,burst-regs-num = <99>;
				nvidia,emc-trimmers-num = <30>;
				nvidia,burst-up-down-regs-num = <11>;
				nvidia,emc-registers = <0x00000003 0x00000011
					0x00000000 0x00000002 0x00000000 0x00000004
					0x0000000a 0x00000003 0x0000000b 0x00000000
					0x00000000 0x00000003 0x00000001 0x00000000
					0x00000005 0x00000005 0x00000006 0x00010000
					0x00000000 0x00000004 0x0000000d 0x00000202
					0x00000000 0x00000080 0x00000002 0x00000002
					0x00000001 0x00000000 0x0000000f 0x0000000f
					0x00000013 0x00000013 0x00000004 0x00000004
					0x00000004 0x00000003 0x00000000 0x00000004
					0x00000005 0x00000213 0x00000006 0x00000020
					0x00000000 0x0000aa88 0x002c00a0 0x00008000
					0x0006c000 0x0006c000 0x0006c000 0x0006c000
					0x00000000 0x00000000 0x00000000 0x00000000
					0x00000000 0x00000000 0x00000000 0x00000000
					0x001112a0 0x00000000 0x0000a11c 0x00000000
					0x77ffc085 0x81f1f108 0x03035504 0x00000000
					0x0000003f 0x00000000 0x02000000 0x00000802
					0x00000000 0x00000042 0x000c000c 0x000c000c
					0x00000000 0x00000000 0x00000000 0x00000000
					0x8000050e 0x1f7df7df 0x0000001f 0x00000001
					0x80000076 0x00000001 0x00000001 0x00000002
					0x00000000 0x00000001 0x00000001 0x00000002
					0x00000008 0x00000002 0x00000001 0x00000003
					0x00000006 0x06030102 0x000a0402 0x74230403
					0x001f0000>;
				nvidia,emc-trimmers-0 = <0x00000000 0x00000004
					0x00000007 0x00000004 0x00000004 0x0006c000
					0x00000009 0x00000000 0x0000000d 0x00208208
					0x20820800 0x00048000 0xa0f10000 0x00000000
					0x00000000 0x00000000 0x00000000 0x00000000
					0x0006c000 0x0006c000 0x0006c000 0x00048000
					0x00048000 0x00048000 0x00000000 0x00000000
					0x00000000 0x00000000 0x00000000 0x00000000>;
				nvidia,emc-trimmers-1 = <0x00000000 0x00000004
					0x00000007 0x00000004 0x00000004 0x0006c000
					0x00000009 0x00000000 0x0000000d 0x00208208
					0x20820800 0x00048000 0xa8f10000 0x00000000
					0x00000000 0x00000000 0x00000000 0x00000000
					0x0006c000 0x0006c000 0x0006c000 0x00048000
					0x00048000 0x00048000 0x00000000 0x00000000
					0x00000000 0x00000000 0x00000000 0x00000000>;
				nvidia,emc-burst-up-down-regs = <0x00000046 0x00690069
					0x00690075 0x0081008d 0x0000008d 0x008d008d
					0x00bc008d 0x000000bc 0x00bc00bc 0x00ff00ff
					0x00ff00ff>;
				nvidia,emc-zcal-cnt-long = <0x00000042>;
				nvidia,emc-acal-interval = <0x001fffff>;
				nvidia,emc-cfg = <0x7320000e>;
				nvidia,emc-mode-reset = <0x80001221>;
				nvidia,emc-mode-1 = <0x80100003>;
				nvidia,emc-mode-2 = <0x80200008>;
				nvidia,emc-mode-4 = <0x00000000>;
				nvidia,emc-clock-latency-change = <10720>;
			};
			emc-table@102000 {
				compatible = "nvidia,tegra11-emc-table";
				clock-frequency = <102000>;
				nvidia,revision = <0x41>;
				nvidia,src-sel-reg = <0x40000006>;
				nvidia,emc-min-mv = <900>;
				nvidia,burst-regs-num = <99>;
				nvidia,emc-trimmers-num = <30>;
				nvidia,burst-up-down-regs-num = <11>;
				nvidia,emc-registers = <0x00000004 0x0000001a
					0x00000000 0x00000003 0x00000001 0x00000004
					0x0000000a 0x00000003 0x0000000b 0x00000001
					0x00000001 0x00000003 0x00000001 0x00000000
					0x00000005 0x00000005 0x00000006 0x00010000
					0x00000000 0x00000004 0x0000000d 0x00000303
					0x00000000 0x000000c0 0x00000002 0x00000002
					0x00000001 0x00000000 0x00000018 0x0000000f
					0x0000001c 0x0000001c 0x00000004 0x00000004
					0x00000004 0x00000005 0x00000000 0x00000004
					0x00000005 0x0000031c 0x00000006 0x00000020
					0x00000000 0x0000aa88 0x002c00a0 0x00008000
					0x0006c000 0x0006c000 0x0006c000 0x0006c000
					0x00000000 0x00000000 0x00000000 0x00000000
					0x00000000 0x00000000 0x00000000 0x00000000
					0x001112a0 0x00000000 0x0000a11c 0x00000000
					0x77ffc085 0x81f1f108 0x03035504 0x00000000
					0x0000003f 0x00000000 0x02000000 0x00000802
					0x00000000 0x00000042 0x000c000c 0x000c000c
					0x00000000 0x00000000 0x00000000 0x00000000
					0x80000714 0x1f7df7df 0x0000001f 0x08000001
					0x80000098 0x00000001 0x00000001 0x00000003
					0x00000000 0x00000002 0x00000001 0x00000002
					0x00000008 0x00000002 0x00000001 0x00000003
					0x00000006 0x06030102 0x000a0403 0x73c30504
					0x001f0000>;
				nvidia,emc-trimmers-0 = <0x00000000 0x00000004
					0x00000007 0x00000004 0x00000004 0x0006c000
					0x00000009 0x00000000 0x0000000d 0x00208208
					0x20820800 0x00048000 0xa0f10000 0x00000000
					0x00000000 0x00000000 0x00000000 0x00000000
					0x0006c000 0x0006c000 0x0006c000 0x00048000
					0x00048000 0x00048000 0x00000000 0x00000000
					0x00000000 0x00000000 0x00000000 0x00000000>;
				nvidia,emc-trimmers-1 = <0x00000000 0x00000004
					0x00000007 0x00000004 0x00000004 0x0006c000
					0x00000009 0x00000000 0x0000000d 0x00208208
					0x20820800 0x00048000 0xa8f10000 0x00000000
					0x00000000 0x00000000 0x00000000 0x00000000
					0x0006c000 0x0006c000 0x0006c000 0x00048000
					0x00048000 0x00048000 0x00000000 0x00000000
					0x00000000 0x00000000 0x00000000 0x00000000>;
				nvidia,emc-burst-up-down-regs = <0x00000068 0x00460046
					0x0046004e 0x0056005e 0x0000005e 0x005e005e
					0x007d005e 0x0000007d 0x007d007d 0x00ff00ff
					0x00ff00ff>;
				nvidia,emc-zcal-cnt-long = <0x00000042>;
				nvidia,emc-acal-interval = <0x001fffff>;
				nvidia,emc-cfg = <0x7320000e>;
				nvidia,emc-mode-reset = <0x80001221>;
				nvidia,emc-mode-1 = <0x80100003>;
				nvidia,emc-mode-2 = <0x80200008>;
				nvidia,emc-mode-4 = <0x00000000>;
				nvidia,emc-clock-latency-change = <6890>;
			};
			emc-table@204000 {
				compatible = "nvidia,tegra11-emc-table";
				clock-frequency = <204000>;
				nvidia,revision = <0x41>;
				nvidia,src-sel-reg = <0x40000002>;
				nvidia,emc-min-mv = <900>;
				nvidia,burst-regs-num = <99>;
				nvidia,emc-trimmers-num = <30>;
				nvidia,burst-up-down-regs-num = <11>;
				nvidia,emc-registers = <0x00000009 0x00000035
					0x00000000 0x00000007 0x00000002 0x00000004
					0x0000000a 0x00000003 0x0000000b 0x00000002
					0x00000002 0x00000003 0x00000001 0x00000000
					0x00000005 0x00000005 0x00000006 0x00010000
					0x00000000 0x00000004 0x0000000d 0x00000607
					0x00000000 0x00000181 0x00000002 0x00000002
					0x00000001 0x00000000 0x00000032 0x0000000f
					0x00000038 0x00000038 0x00000004 0x00000004
					0x00000004 0x00000009 0x00000000 0x00000004
					0x00000005 0x00000638 0x00000006 0x00000020
					0x00000000 0x0000aa88 0x000000a0 0x00008000
					0x0006c000 0x0006c000 0x0006c000 0x0006c000
					0x00000000 0x00000000 0x00000000 0x00000000
					0x00000000 0x00000000 0x00000000 0x00000000
					0x001112a0 0x00000000 0x0000a11c 0x00000000
					0x77ffc085 0x81f1f108 0x05057404 0x0000001f
					0x0000003f 0x00000000 0x02000000 0x00000802
					0x00020000 0x00000100 0x000c000c 0x000c000c
					0x00000000 0x00000000 0x00000000 0x00000000
					0x80000d22 0x1f7df7df 0x0000001f 0x01000003
					0x800000fe 0x00000001 0x00000001 0x00000005
					0x00000002 0x00000004 0x00000001 0x00000002
					0x00000008 0x00000002 0x00000001 0x00000003
					0x00000006 0x06030102 0x000a0405 0x73840a06
					0x001f0000>;
				nvidia,emc-trimmers-0 = <0x00000000 0x00000004
					0x00000007 0x00000004 0x00000004 0x0006c000
					0x00000009 0x00000000 0x0000000d 0x0079e79e
					0x20820800 0x00048000 0xa0f10000 0x00000000
					0x00000808 0x00000000 0x00000000 0x00000000
					0x0006c000 0x0006c000 0x0006c000 0x00048000
					0x00048000 0x00048000 0x00000000 0x00000000
					0x00000000 0x00000000 0x00000000 0x00000000>;
				nvidia,emc-trimmers-1 = <0x00000000 0x00000004
					0x00000007 0x00000004 0x00000004 0x0006c000
					0x00000009 0x00000000 0x0000000d 0x0079e79e
					0x20820800 0x00048000 0xa8f10000 0x00000000
					0x00000808 0x00000000 0x00000000 0x00000000
					0x0006c000 0x0006c000 0x0006c000 0x00048000
					0x00048000 0x00048000 0x00000000 0x00000000
					0x00000000 0x00000000 0x00000000 0x00000000>;
				nvidia,emc-burst-up-down-regs = <0x000000d0 0x00230023
					0x00230027 0x002b002f 0x0000002f 0x002f002f
					0x003e002f 0x0000003e 0x003e003e 0x00ff00c8
					0x00ff00ff>;
				nvidia,emc-zcal-cnt-long = <0x00000042>;
				nvidia,emc-acal-interval = <0x001fffff>;
				nvidia,emc-cfg = <0x7320000e>;
				nvidia,emc-mode-reset = <0x80001221>;
				nvidia,emc-mode-1 = <0x80100003>;
				nvidia,emc-mode-2 = <0x80200008>;
				nvidia,emc-mode-4 = <0x00000000>;
				nvidia,emc-clock-latency-change = <3420>;
			};
			emc-table@312000 {
				compatible = "nvidia,tegra11-emc-table";
				clock-frequency = <312000>;
				nvidia,revision = <0x41>;
				nvidia,src-sel-reg = <0x24000002>;
				nvidia,emc-min-mv = <1000>;
				nvidia,burst-regs-num = <99>;
				nvidia,emc-trimmers-num = <30>;
				nvidia,burst-up-down-regs-num = <11>;
				nvidia,emc-registers = <0x0000000e 0x00000050
					0x00000000 0x00000009 0x00000003 0x00000004
					0x00000008 0x00000002 0x00000009 0x00000003
					0x00000003 0x00000002 0x00000001 0x00000000
					0x00000004 0x00000004 0x00000007 0x00080006
					0x00000000 0x00000004 0x0000000d 0x00000945
					0x00000000 0x00000251 0x00000001 0x00000008
					0x00000001 0x00000000 0x0000004d 0x0000000e
					0x00000055 0x00000200 0x00000004 0x00000004
					0x00000004 0x0000000d 0x00000000 0x00000004
					0x00000005 0x00000986 0x00000006 0x00000020
					0x00000000 0x0000ba88 0x002c00a0 0x00008000
					0x00030000 0x00030000 0x00030000 0x00030000
					0x00028000 0x00028000 0x00028000 0x00028000
					0x00000000 0x00000000 0x00000000 0x00000000
					0x001112a0 0x00000000 0x0001013d 0x00000000
					0x77ffc085 0x81f1f108 0x03035504 0x00000000
					0x0000003f 0x00000000 0x02000000 0x00000802
					0x00020000 0x00000100 0x0171000c 0x0171000c
					0x00000000 0x00000000 0x00000000 0x00000000
					0x80001395 0x1f7df7df 0x0000001f 0x0b000004
					0x8000016a 0x00000001 0x00000002 0x00000007
					0x00000004 0x00000006 0x00000001 0x00000002
					0x00000007 0x00000002 0x00000002 0x00000004
					0x00000006 0x06040202 0x000b0607 0x76e50f08
					0x001f0000>;
				nvidia,emc-trimmers-0 = <0x00000000 0x00000006
					0x00000007 0x00000005 0x00000004 0x00030000
					0x0000000b 0x00028000 0x0000000d 0x00208208
					0x10410400 0x00030000 0xa0f10000 0x00014000
					0x00000000 0x00000000 0x00000000 0x00014000
					0x00030000 0x00030000 0x00030000 0x00030000
					0x00030000 0x00030000 0x00000000 0x00000000
					0x00000000 0x00028000 0x00028000 0x00028000>;
				nvidia,emc-trimmers-1 = <0x00000000 0x00000006
					0x00000007 0x00000005 0x00000004 0x00030000
					0x0000000b 0x00028000 0x0000000d 0x00208208
					0x10410400 0x00030000 0xa8f10000 0x00014000
					0x00000000 0x00000000 0x00000000 0x00014000
					0x00030000 0x00030000 0x00030000 0x00030000
					0x00030000 0x00030000 0x00000000 0x00000000
					0x00000000 0x00028000 0x00028000 0x00028000>;
				nvidia,emc-burst-up-down-regs = <0x00000140 0x00170017
					0x00170019 0x001c001e 0x0000001e 0x001e001e
					0x0029001e 0x00000029 0x00290029 0x00ff0082
					0x00ff00ff>;
				nvidia,emc-zcal-cnt-long = <0x00000042>;
				nvidia,emc-acal-interval = <0x001fffff>;
				nvidia,emc-cfg = <0x5320000e>;
				nvidia,emc-mode-reset = <0x80000321>;
				nvidia,emc-mode-1 = <0x80100002>;
				nvidia,emc-mode-2 = <0x80200000>;
				nvidia,emc-mode-4 = <0x00000000>;
				nvidia,emc-clock-latency-change = <2680>;
			};
			emc-table@408000 {
				compatible = "nvidia,tegra11-emc-table";
				clock-frequency = <408000>;
				nvidia,revision = <0x41>;
				nvidia,src-sel-reg = <0x40000000>;
				nvidia,emc-min-mv = <1000>;
				nvidia,burst-regs-num = <99>;
				nvidia,emc-trimmers-num = <30>;
				nvidia,burst-up-down-regs-num = <11>;
				nvidia,emc-registers = <0x00000012 0x00000069
					0x00000000 0x0000000d 0x00000004 0x00000005
					0x00000009 0x00000002 0x0000000c 0x00000004
					0x00000004 0x00000002 0x00000001 0x00000000
					0x00000004 0x00000004 0x00000007 0x00080006
					0x00000000 0x00000004 0x0000000e 0x00000c2f
					0x00000000 0x0000030b 0x00000001 0x00000008
					0x00000001 0x00000000 0x00000066 0x00000011
					0x0000006f 0x00000200 0x00000004 0x00000004
					0x00000004 0x00000011 0x00000000 0x00000004
					0x00000005 0x00000c70 0x00000007 0x00000020
					0x00000000 0x0000ba88 0x002c0080 0x00008000
					0x00020000 0x00020000 0x00020000 0x00020000
					0x00000000 0x00000000 0x00000000 0x00000000
					0x00000000 0x00000000 0x00000000 0x00000000
					0x001112a0 0x00000000 0x0001013d 0x00000000
					0x77ffc085 0x81f1f108 0x03035504 0x00000000
					0x0000003f 0x00000000 0x02000000 0x00000802
					0x00020000 0x00000100 0x0158000c 0x0158000c
					0x00000000 0x00000000 0x00000000 0x00000000
					0x80001944 0x1f7df7df 0x0000001f 0x02000006
					0x80000190 0x00000001 0x00000002 0x0000000a
					0x00000006 0x00000008 0x00000001 0x00000002
					0x00000009 0x00000002 0x00000002 0x00000004
					0x00000006 0x06040202 0x000e070a 0x7547130b
					0x001f0000>;
				nvidia,emc-trimmers-0 = <0x00000000 0x00000004
					0x00000008 0x00000005 0x00000004 0x00020000
					0x0000000c 0x00000000 0x0000000e 0x00208208
					0x10410400 0x00020000 0xa0f10000 0x00000005
					0x00000000 0x00000000 0x00000005 0x00000005
					0x00020000 0x00020000 0x00020000 0x00020000
					0x00020000 0x00020000 0x00000000 0x00000000
					0x00000000 0x00000000 0x00000000 0x00000000>;
				nvidia,emc-trimmers-1 = <0x00000000 0x00000004
					0x00000008 0x00000005 0x00000004 0x00020000
					0x0000000c 0x00000000 0x0000000e 0x00208208
					0x10410400 0x00020000 0xa8f10000 0x00000005
					0x00000000 0x00000000 0x00000005 0x00000005
					0x00020000 0x00020000 0x00020000 0x00020000
					0x00020000 0x00020000 0x00000000 0x00000000
					0x00000000 0x00000000 0x00000000 0x00000000>;
				nvidia,emc-burst-up-down-regs = <0x000000d1 0x00110011
					0x00110013 0x00150017 0x00000017 0x00170017
					0x001f0017 0x0000001f 0x001f001f 0x00d30064
					0x00d300d3>;
				nvidia,emc-zcal-cnt-long = <0x00000042>;
				nvidia,emc-acal-interval = <0x001fffff>;
				nvidia,emc-cfg = <0x53200006>;
				nvidia,emc-mode-reset = <0x80000731>;
				nvidia,emc-mode-1 = <0x80100002>;
				nvidia,emc-mode-2 = <0x80200008>;
				nvidia,emc-mode-4 = <0x00000000>;
				nvidia,emc-clock-latency-change = <1750>;
			};
			emc-table@792000 {
				compatible = "nvidia,tegra11-emc-table";
				clock-frequency = <792000>;
				nvidia,revision = <0x41>;
				nvidia,src-sel-reg = <0x80000000>;
				nvidia,emc-min-mv = <1100>;
				nvidia,burst-regs-num = <99>;
				nvidia,emc-trimmers-num = <30>;
				nvidia,burst-up-down-regs-num = <11>;
				nvidia,emc-registers = <0x00000024 0x000000cd
					0x00000000 0x00000019 0x0000000a 0x00000009
					0x0000000d 0x00000004 0x00000013 0x0000000a
					0x0000000a 0x00000003 0x00000001 0x00000000
					0x00000006 0x00000006 0x0000000b 0x000d000a
					0x00000000 0x00000008 0x00000014 0x000017e4
					0x00000000 0x000005f9 0x00000003 0x00000012
					0x00000001 0x00000000 0x000000c6 0x00000018
					0x000000d6 0x00000200 0x00000005 0x00000005
					0x00000005 0x00000020 0x00000000 0x00000007
					0x00000008 0x00001825 0x0000000a 0x80000020
					0x00000000 0x0000ba88 0xf0070191 0x00008000
					0x0000000a 0x0000000a 0x0000000a 0x0000000a
					0x00000000 0x00000000 0x00000000 0x00000000
					0x00000000 0x00000000 0x00000000 0x00000000
					0x001112a0 0x00000000 0x0000013d 0x00000000
					0x77ffc084 0x81f1f508 0x07077704 0x00000000
					0x0000003f 0x00000000 0x02000000 0x00000802
					0x00020000 0x00000100 0x00f8000f 0x00f8000f
					0x00000000 0x00000000 0x00000000 0x00000000
					0x80003018 0x1f7df7df 0x0000001f 0x0e00000b
					0x80000190 0x00000004 0x00000005 0x00000013
					0x0000000c 0x0000000f 0x00000002 0x00000003
					0x0000000c 0x00000002 0x00000002 0x00000006
					0x00000008 0x08060202 0x00170e13 0x734c2414
					0x001f0000>;
				nvidia,emc-trimmers-0 = <0x00000000 0x00000006
					0x0000000b 0x00000008 0x00000006 0x0000000a
					0x0000000d 0x00000000 0x00000014 0x00249249
					0x10410400 0x0000000a 0xa0f10f0f 0x0000000d
					0x00000b0b 0x00000000 0x0000000d 0x0000000d
					0x0000000a 0x0000000a 0x0000000a 0x0000000a
					0x0000000a 0x0000000a 0x00000000 0x00000000
					0x00000000 0x00000000 0x00000000 0x00000000>;
				nvidia,emc-trimmers-1 = <0x00000000 0x00000006
					0x0000000b 0x00000008 0x00000006 0x0000000a
					0x0000000d 0x00000000 0x00000014 0x00249249
					0x10410400 0x0000000a 0xa8f10f0f 0x0000000d
					0x00000b0b 0x00000000 0x0000000d 0x0000000d
					0x0000000a 0x0000000a 0x0000000a 0x0000000a
					0x0000000a 0x0000000a 0x00000000 0x00000000
					0x00000000 0x00000000 0x00000000 0x00000000>;
				nvidia,emc-burst-up-down-regs = <0x00000196 0x00090009
					0x0009000a 0x000b000c 0x0000000c 0x000c000c
					0x0010000c 0x00000010 0x00100010 0x006d0033
					0x006d006d>;
				nvidia,emc-zcal-cnt-long = <0x00000042>;
				nvidia,emc-acal-interval = <0x001fffff>;
				nvidia,emc-cfg = <0x73000000>;
				nvidia,emc-mode-reset = <0x80000d71>;
				nvidia,emc-mode-1 = <0x80100002>;
				nvidia,emc-mode-2 = <0x80200218>;
				nvidia,emc-mode-4 = <0x00000000>;
				nvidia,emc-clock-latency-change = <1200>;
			};
		};
		chip-sku@-1 {
			emc-table@12750 {
				compatible = "nvidia,tegra11-emc-table";
				clock-frequency = <12750>;
				nvidia,revision = <0x41>;
				nvidia,src-sel-reg = <0x4000003e>;
				nvidia,emc-min-mv = <900>;
				nvidia,burst-regs-num = <99>;
				nvidia,emc-trimmers-num = <30>;
				nvidia,burst-up-down-regs-num = <11>;
				nvidia,emc-registers = <0x00000000 0x00000003
					0x00000000 0x00000000 0x00000000 0x00000004
					0x0000000a 0x00000003 0x0000000b 0x00000000
					0x00000000 0x00000003 0x00000001 0x00000000
					0x00000005 0x00000005 0x00000005 0x00010000
					0x00000000 0x00000004 0x0000000d 0x00000060
					0x00000000 0x00000018 0x00000002 0x00000002
					0x00000001 0x00000000 0x00000007 0x0000000f
					0x00000005 0x00000005 0x00000004 0x00000004
					0x00000004 0x00000001 0x00000000 0x00000004
					0x00000005 0x00000064 0x00000005 0x00000020
					0x00000000 0x0000aa88 0x002c00a0 0x00008000
					0x00060000 0x00060000 0x00060000 0x00060000
					0x00000000 0x00000000 0x00000000 0x00000000
					0x00000000 0x00000000 0x00000000 0x00000000
					0x001112a0 0x00000000 0x0000a11c 0x00000000
					0x77ffc084 0x81f1f108 0x03035504 0x00000000
					0x0000003f 0x00000000 0x02000000 0x00000802
					0x00000000 0x00000042 0x000c000c 0x000c000c
					0x00000000 0x00000000 0x00000000 0x00000000
					0x800001c6 0x1f7df7df 0x0000001f 0x40040001
					0x8000003f 0x00000001 0x00000001 0x00000002
					0x00000000 0x00000001 0x00000001 0x00000002
					0x00000008 0x00000002 0x00000001 0x00000003
					0x00000006 0x06030102 0x000a0402 0x77e30303
					0x001f0000>;
				nvidia,emc-trimmers-0 = <0x00000000 0x00000006
					0x00000006 0x00000005 0x00000004 0x00060000
					0x00000009 0x00000000 0x0000000d 0x0079e79e
					0x20820800 0x00048000 0xa0f10000 0x00000000
					0x00000808 0x00000000 0x00000000 0x00000000
					0x00060000 0x00060000 0x00060000 0x00048000
					0x00048000 0x00048000 0x00000000 0x00000000
					0x00000000 0x00000000 0x00000000 0x00000000>;
				nvidia,emc-trimmers-1 = <0x00000000 0x00000006
					0x00000006 0x00000005 0x00000004 0x00060000
					0x00000009 0x00000000 0x0000000d 0x0079e79e
					0x20820800 0x00048000 0xa8f10000 0x00000000
					0x00000808 0x00000000 0x00000000 0x00000000
					0x00060000 0x00060000 0x00060000 0x00048000
					0x00048000 0x00048000 0x00000000 0x00000000
					0x00000000 0x00000000 0x00000000 0x00000000>;
				nvidia,emc-burst-up-down-regs = <0x0000000e 0x00ff00ff
					0x00ff00ff 0x00ff00ff 0x000000ff 0x00ff00ff
					0x00ff00ff 0x000000ff 0x00ff00ff 0x00ff00ff
					0x00ff00ff>;
				nvidia,emc-zcal-cnt-long = <0x00000042>;
				nvidia,emc-acal-interval = <0x001fffff>;
				nvidia,emc-cfg = <0x7320000e>;
				nvidia,emc-mode-reset = <0x80001221>;
				nvidia,emc-mode-1 = <0x80100003>;
				nvidia,emc-mode-2 = <0x80200008>;
				nvidia,emc-mode-4 = <0x00000000>;
				nvidia,emc-clock-latency-change = <57820>;
			};
			emc-table@20400 {
				compatible = "nvidia,tegra11-emc-table";
				clock-frequency = <20400>;
				nvidia,revision = <0x41>;
				nvidia,src-sel-reg = <0x40000026>;
				nvidia,emc-min-mv = <900>;
				nvidia,burst-regs-num = <99>;
				nvidia,emc-trimmers-num = <30>;
				nvidia,burst-up-down-regs-num = <11>;
				nvidia,emc-registers = <0x00000000 0x00000005
					0x00000000 0x00000000 0x00000000 0x00000004
					0x0000000a 0x00000003 0x0000000b 0x00000000
					0x00000000 0x00000003 0x00000001 0x00000000
					0x00000005 0x00000005 0x00000005 0x00010000
					0x00000000 0x00000004 0x0000000d 0x0000009a
					0x00000000 0x00000026 0x00000002 0x00000002
					0x00000001 0x00000000 0x00000007 0x0000000f
					0x00000006 0x00000006 0x00000004 0x00000004
					0x00000004 0x00000001 0x00000000 0x00000004
					0x00000005 0x000000a0 0x00000005 0x00000020
					0x00000000 0x0000aa88 0x002c00a0 0x00008000
					0x00060000 0x00060000 0x00060000 0x00060000
					0x00000000 0x00000000 0x00000000 0x00000000
					0x00000000 0x00000000 0x00000000 0x00000000
					0x001112a0 0x00000000 0x0000a11c 0x00000000
					0x77ffc084 0x81f1f108 0x03035504 0x00000000
					0x0000003f 0x00000000 0x02000000 0x00000802
					0x00000000 0x00000042 0x000c000c 0x000c000c
					0x00000000 0x00000000 0x00000000 0x00000000
					0x8000023a 0x1f7df7df 0x0000001f 0x40020001
					0x80000046 0x00000001 0x00000001 0x00000002
					0x00000000 0x00000001 0x00000001 0x00000002
					0x00000008 0x00000002 0x00000001 0x00000003
					0x00000006 0x06030102 0x000a0402 0x76230303
					0x001f0000>;
				nvidia,emc-trimmers-0 = <0x00000000 0x00000006
					0x00000006 0x00000005 0x00000004 0x00060000
					0x00000009 0x00000000 0x0000000d 0x0079e79e
					0x20820800 0x00048000 0xa0f10000 0x00000000
					0x00000808 0x00000000 0x00000000 0x00000000
					0x00060000 0x00060000 0x00060000 0x00048000
					0x00048000 0x00048000 0x00000000 0x00000000
					0x00000000 0x00000000 0x00000000 0x00000000>;
				nvidia,emc-trimmers-1 = <0x00000000 0x00000006
					0x00000006 0x00000005 0x00000004 0x00060000
					0x00000009 0x00000000 0x0000000d 0x0079e79e
					0x20820800 0x00048000 0xa8f10000 0x00000000
					0x00000808 0x00000000 0x00000000 0x00000000
					0x00060000 0x00060000 0x00060000 0x00048000
					0x00048000 0x00048000 0x00000000 0x00000000
					0x00000000 0x00000000 0x00000000 0x00000000>;
				nvidia,emc-burst-up-down-regs = <0x00000014 0x00ff00ff
					0x00ff00ff 0x00ff00ff 0x000000ff 0x00ff00ff
					0x00ff00ff 0x000000ff 0x00ff00ff 0x00ff00ff
					0x00ff00ff>;
				nvidia,emc-zcal-cnt-long = <0x00000042>;
				nvidia,emc-acal-interval = <0x001fffff>;
				nvidia,emc-cfg = <0x7320000e>;
				nvidia,emc-mode-reset = <0x80001221>;
				nvidia,emc-mode-1 = <0x80100003>;
				nvidia,emc-mode-2 = <0x80200008>;
				nvidia,emc-mode-4 = <0x00000000>;
				nvidia,emc-clock-latency-change = <35610>;
			};
			emc-table@40800 {
				compatible = "nvidia,tegra11-emc-table";
				clock-frequency = <40800>;
				nvidia,revision = <0x41>;
				nvidia,src-sel-reg = <0x40000012>;
				nvidia,emc-min-mv = <900>;
				nvidia,burst-regs-num = <99>;
				nvidia,emc-trimmers-num = <30>;
				nvidia,burst-up-down-regs-num = <11>;
				nvidia,emc-registers = <0x00000001 0x0000000a
					0x00000000 0x00000001 0x00000000 0x00000004
					0x0000000a 0x00000003 0x0000000b 0x00000000
					0x00000000 0x00000003 0x00000001 0x00000000
					0x00000005 0x00000005 0x00000005 0x00010000
					0x00000000 0x00000004 0x0000000d 0x00000134
					0x00000000 0x0000004d 0x00000002 0x00000002
					0x00000001 0x00000000 0x00000008 0x0000000f
					0x0000000c 0x0000000c 0x00000004 0x00000004
					0x00000004 0x00000002 0x00000000 0x00000004
					0x00000005 0x0000013f 0x00000005 0x00000020
					0x00000000 0x0000aa88 0x002c00a0 0x00008000
					0x00060000 0x00060000 0x00060000 0x00060000
					0x00000000 0x00000000 0x00000000 0x00000000
					0x00000000 0x00000000 0x00000000 0x00000000
					0x001112a0 0x00000000 0x0000a11c 0x00000000
					0x77ffc084 0x81f1f108 0x03035504 0x00000000
					0x0000003f 0x00000000 0x02000000 0x00000802
					0x00000000 0x00000042 0x000c000c 0x000c000c
					0x00000000 0x00000000 0x00000000 0x00000000
					0x80000370 0x1f7df7df 0x0000001f 0xa0000001
					0x8000005b 0x00000001 0x00000001 0x00000002
					0x00000000 0x00000001 0x00000001 0x00000002
					0x00000008 0x00000002 0x00000001 0x00000003
					0x00000006 0x06030102 0x000a0402 0x74a30303
					0x001f0000>;
				nvidia,emc-trimmers-0 = <0x00000000 0x00000006
					0x00000006 0x00000005 0x00000004 0x00060000
					0x00000009 0x00000000 0x0000000d 0x0079e79e
					0x20820800 0x00048000 0xa0f10000 0x00000000
					0x00000808 0x00000000 0x00000000 0x00000000
					0x00060000 0x00060000 0x00060000 0x00048000
					0x00048000 0x00048000 0x00000000 0x00000000
					0x00000000 0x00000000 0x00000000 0x00000000>;
				nvidia,emc-trimmers-1 = <0x00000000 0x00000006
					0x00000006 0x00000005 0x00000004 0x00060000
					0x00000009 0x00000000 0x0000000d 0x0079e79e
					0x20820800 0x00048000 0xa8f10000 0x00000000
					0x00000808 0x00000000 0x00000000 0x00000000
					0x00060000 0x00060000 0x00060000 0x00048000
					0x00048000 0x00048000 0x00000000 0x00000000
					0x00000000 0x00000000 0x00000000 0x00000000>;
				nvidia,emc-burst-up-down-regs = <0x0000002a 0x00b000b0
					0x00b000c4 0x00d700eb 0x000000eb 0x00eb00eb
					0x00ff00eb 0x000000ff 0x00ff00ff 0x00ff00ff
					0x00ff00ff>;
				nvidia,emc-zcal-cnt-long = <0x00000042>;
				nvidia,emc-acal-interval = <0x001fffff>;
				nvidia,emc-cfg = <0x7320000e>;
				nvidia,emc-mode-reset = <0x80001221>;
				nvidia,emc-mode-1 = <0x80100003>;
				nvidia,emc-mode-2 = <0x80200008>;
				nvidia,emc-mode-4 = <0x00000000>;
				nvidia,emc-clock-latency-change = <20850>;
			};
			emc-table@68000 {
				compatible = "nvidia,tegra11-emc-table";
				clock-frequency = <68000>;
				nvidia,revision = <0x41>;
				nvidia,src-sel-reg = <0x4000000a>;
				nvidia,emc-min-mv = <900>;
				nvidia,burst-regs-num = <99>;
				nvidia,emc-trimmers-num = <30>;
				nvidia,burst-up-down-regs-num = <11>;
				nvidia,emc-registers = <0x00000003 0x00000011
					0x00000000 0x00000002 0x00000000 0x00000004
					0x0000000a 0x00000003 0x0000000b 0x00000000
					0x00000000 0x00000003 0x00000001 0x00000000
					0x00000005 0x00000005 0x00000005 0x00010000
					0x00000000 0x00000004 0x0000000c 0x00000202
					0x00000000 0x00000080 0x00000002 0x00000002
					0x00000001 0x00000000 0x0000000f 0x0000000f
					0x00000013 0x00000013 0x00000004 0x00000004
					0x00000004 0x00000003 0x00000000 0x00000004
					0x00000005 0x00000213 0x00000005 0x00000020
					0x00000000 0x0000aa88 0x002c00a0 0x00008000
					0x00060000 0x00060000 0x00060000 0x00060000
					0x00000000 0x00000000 0x00000000 0x00000000
					0x00000000 0x00000000 0x00000000 0x00000000
					0x001112a0 0x00000000 0x0000a11c 0x00000000
					0x77ffc084 0x81f1f108 0x03035504 0x00000000
					0x0000003f 0x00000000 0x02000000 0x00000802
					0x00000000 0x00000042 0x000c000c 0x000c000c
					0x00000000 0x00000000 0x00000000 0x00000000
					0x8000050e 0x1f7df7df 0x0000001f 0x00000001
					0x80000076 0x00000001 0x00000001 0x00000002
					0x00000000 0x00000001 0x00000001 0x00000002
					0x00000008 0x00000002 0x00000001 0x00000003
					0x00000006 0x06030102 0x000a0402 0x74230403
					0x001f0000>;
				nvidia,emc-trimmers-0 = <0x00000000 0x00000006
					0x00000006 0x00000005 0x00000004 0x00060000
					0x0000000a 0x00000000 0x0000000c 0x0079e79e
					0x20820800 0x00048000 0xa0f10000 0x00000000
					0x00000808 0x00000000 0x00000000 0x00000000
					0x00060000 0x00060000 0x00060000 0x00048000
					0x00048000 0x00048000 0x00000000 0x00000000
					0x00000000 0x00000000 0x00000000 0x00000000>;
				nvidia,emc-trimmers-1 = <0x00000000 0x00000006
					0x00000006 0x00000005 0x00000004 0x00060000
					0x0000000a 0x00000000 0x0000000c 0x0079e79e
					0x20820800 0x00048000 0xa8f10000 0x00000000
					0x00000808 0x00000000 0x00000000 0x00000000
					0x00060000 0x00060000 0x00060000 0x00048000
					0x00048000 0x00048000 0x00000000 0x00000000
					0x00000000 0x00000000 0x00000000 0x00000000>;
				nvidia,emc-burst-up-down-regs = <0x00000046 0x00690069
					0x00690075 0x0081008d 0x0000008d 0x008d008d
					0x00bc008d 0x000000bc 0x00bc00bc 0x00ff00ff
					0x00ff00ff>;
				nvidia,emc-zcal-cnt-long = <0x00000042>;
				nvidia,emc-acal-interval = <0x001fffff>;
				nvidia,emc-cfg = <0x7320000e>;
				nvidia,emc-mode-reset = <0x80001221>;
				nvidia,emc-mode-1 = <0x80100003>;
				nvidia,emc-mode-2 = <0x80200008>;
				nvidia,emc-mode-4 = <0x00000000>;
				nvidia,emc-clock-latency-change = <10720>;
			};
			emc-table@102000 {
				compatible = "nvidia,tegra11-emc-table";
				clock-frequency = <102000>;
				nvidia,revision = <0x41>;
				nvidia,src-sel-reg = <0x40000006>;
				nvidia,emc-min-mv = <900>;
				nvidia,burst-regs-num = <99>;
				nvidia,emc-trimmers-num = <30>;
				nvidia,burst-up-down-regs-num = <11>;
				nvidia,emc-registers = <0x00000004 0x0000001a
					0x00000000 0x00000003 0x00000001 0x00000004
					0x0000000a 0x00000003 0x0000000b 0x00000001
					0x00000001 0x00000003 0x00000001 0x00000000
					0x00000005 0x00000005 0x00000005 0x00010000
					0x00000000 0x00000004 0x0000000c 0x00000303
					0x00000000 0x000000c0 0x00000002 0x00000002
					0x00000001 0x00000000 0x00000018 0x0000000f
					0x0000001c 0x0000001c 0x00000004 0x00000004
					0x00000004 0x00000005 0x00000000 0x00000004
					0x00000005 0x0000031c 0x00000005 0x00000020
					0x00000000 0x0000aa88 0x002c00a0 0x00008000
					0x00060000 0x00060000 0x00060000 0x00060000
					0x00000000 0x00000000 0x00000000 0x00000000
					0x00000000 0x00000000 0x00000000 0x00000000
					0x001112a0 0x00000000 0x0000a11c 0x00000000
					0x77ffc084 0x81f1f108 0x03035504 0x00000000
					0x0000003f 0x00000000 0x02000000 0x00000802
					0x00000000 0x00000042 0x000c000c 0x000c000c
					0x00000000 0x00000000 0x00000000 0x00000000
					0x80000714 0x1f7df7df 0x0000001f 0x08000001
					0x80000098 0x00000001 0x00000001 0x00000003
					0x00000000 0x00000002 0x00000001 0x00000002
					0x00000008 0x00000002 0x00000001 0x00000003
					0x00000006 0x06030102 0x000a0403 0x73c30504
					0x001f0000>;
				nvidia,emc-trimmers-0 = <0x00000000 0x00000006
					0x00000006 0x00000005 0x00000004 0x00060000
					0x0000000a 0x00000000 0x0000000c 0x0079e79e
					0x20820800 0x00048000 0xa0f10000 0x00000000
					0x00000808 0x00000000 0x00000000 0x00000000
					0x00060000 0x00060000 0x00060000 0x00048000
					0x00048000 0x00048000 0x00000000 0x00000000
					0x00000000 0x00000000 0x00000000 0x00000000>;
				nvidia,emc-trimmers-1 = <0x00000000 0x00000006
					0x00000006 0x00000005 0x00000004 0x00060000
					0x0000000a 0x00000000 0x0000000c 0x0079e79e
					0x20820800 0x00048000 0xa8f10000 0x00000000
					0x00000808 0x00000000 0x00000000 0x00000000
					0x00060000 0x00060000 0x00060000 0x00048000
					0x00048000 0x00048000 0x00000000 0x00000000
					0x00000000 0x00000000 0x00000000 0x00000000>;
				nvidia,emc-burst-up-down-regs = <0x00000068 0x00460046
					0x0046004e 0x0056005e 0x0000005e 0x005e005e
					0x007d005e 0x0000007d 0x007d007d 0x00ff00ff
					0x00ff00ff>;
				nvidia,emc-zcal-cnt-long = <0x00000042>;
				nvidia,emc-acal-interval = <0x001fffff>;
				nvidia,emc-cfg = <0x7320000e>;
				nvidia,emc-mode-reset = <0x80001221>;
				nvidia,emc-mode-1 = <0x80100003>;
				nvidia,emc-mode-2 = <0x80200008>;
				nvidia,emc-mode-4 = <0x00000000>;
				nvidia,emc-clock-latency-change = <6890>;
			};
			emc-table@204000 {
				compatible = "nvidia,tegra11-emc-table";
				clock-frequency = <204000>;
				nvidia,revision = <0x41>;
				nvidia,src-sel-reg = <0x40000002>;
				nvidia,emc-min-mv = <1000>;
				nvidia,burst-regs-num = <99>;
				nvidia,emc-trimmers-num = <30>;
				nvidia,burst-up-down-regs-num = <11>;
				nvidia,emc-registers = <0x00000009 0x00000035
					0x00000000 0x00000007 0x00000002 0x00000004
					0x0000000a 0x00000003 0x0000000b 0x00000002
					0x00000002 0x00000003 0x00000001 0x00000000
					0x00000005 0x00000005 0x00000006 0x00010000
					0x00000000 0x00000004 0x0000000d 0x00000607
					0x00000000 0x00000181 0x00000002 0x00000002
					0x00000001 0x00000000 0x00000032 0x0000000f
					0x00000038 0x00000038 0x00000004 0x00000004
					0x00000004 0x00000009 0x00000000 0x00000004
					0x00000005 0x00000638 0x00000006 0x00000020
					0x00000000 0x0000aa88 0x000000a0 0x00008000
					0x00064000 0x00064000 0x00064000 0x00064000
					0x00000000 0x00000000 0x00000000 0x00000000
					0x00000000 0x00000000 0x00000000 0x00000000
					0x001112a0 0x00000000 0x0000a11c 0x00000000
					0x77ffc084 0x81f1f108 0x05057404 0x0000001f
					0x0000003f 0x00000000 0x02000000 0x00000802
					0x00020000 0x00000100 0x000c000c 0x000c000c
					0x00000000 0x00000000 0x00000000 0x00000000
					0x80000d22 0x1f7df7df 0x0000001f 0x01000003
					0x800000fe 0x00000001 0x00000001 0x00000005
					0x00000002 0x00000004 0x00000001 0x00000002
					0x00000008 0x00000002 0x00000001 0x00000003
					0x00000006 0x06030102 0x000a0405 0x73840a06
					0x001f0000>;
				nvidia,emc-trimmers-0 = <0x00000000 0x00000004
					0x00000007 0x00000004 0x00000004 0x00064000
					0x00000009 0x00000000 0x0000000d 0x0079e79e
					0x20820800 0x00048000 0xa0f10000 0x00000000
					0x00000808 0x00000000 0x00000000 0x00000000
					0x00064000 0x00064000 0x00064000 0x00048000
					0x00048000 0x00048000 0x00000000 0x00000000
					0x00000000 0x00000000 0x00000000 0x00000000>;
				nvidia,emc-trimmers-1 = <0x00000000 0x00000004
					0x00000007 0x00000004 0x00000004 0x00064000
					0x00000009 0x00000000 0x0000000d 0x0079e79e
					0x20820800 0x00048000 0xa8f10000 0x00000000
					0x00000808 0x00000000 0x00000000 0x00000000
					0x00064000 0x00064000 0x00064000 0x00048000
					0x00048000 0x00048000 0x00000000 0x00000000
					0x00000000 0x00000000 0x00000000 0x00000000>;
				nvidia,emc-burst-up-down-regs = <0x000000d0 0x00230023
					0x00230027 0x002b002f 0x0000002f 0x002f002f
					0x003e002f 0x0000003e 0x003e003e 0x00ff00c8
					0x00ff00ff>;
				nvidia,emc-zcal-cnt-long = <0x00000042>;
				nvidia,emc-acal-interval = <0x001fffff>;
				nvidia,emc-cfg = <0x7320000e>;
				nvidia,emc-mode-reset = <0x80001221>;
				nvidia,emc-mode-1 = <0x80100003>;
				nvidia,emc-mode-2 = <0x80200008>;
				nvidia,emc-mode-4 = <0x00000000>;
				nvidia,emc-clock-latency-change = <3420>;
			};
			emc-table@408000 {
				compatible = "nvidia,tegra11-emc-table";
				clock-frequency = <408000>;
				nvidia,revision = <0x41>;
				nvidia,src-sel-reg = <0x40000000>;
				nvidia,emc-min-mv = <1100>;
				nvidia,burst-regs-num = <99>;
				nvidia,emc-trimmers-num = <30>;
				nvidia,burst-up-down-regs-num = <11>;
				nvidia,emc-registers = <0x00000012 0x00000069
					0x00000000 0x0000000d 0x00000004 0x00000005
					0x00000009 0x00000002 0x0000000c 0x00000004
					0x00000004 0x00000002 0x00000001 0x00000000
					0x00000004 0x00000004 0x00000007 0x00010000
					0x00000000 0x00000004 0x0000000e 0x00000c2f
					0x00000000 0x0000030b 0x00000001 0x00000008
					0x00000001 0x00000000 0x00000066 0x00000011
					0x0000006f 0x00000200 0x00000004 0x00000004
					0x00000004 0x00000011 0x00000000 0x00000004
					0x00000005 0x00000c70 0x00000006 0x00000020
					0x00000000 0x0000ba88 0x002c0080 0x00008000
					0x00030000 0x00030000 0x00030000 0x00030000
					0x00000000 0x00000000 0x00000000 0x00000000
					0x00000000 0x00000000 0x00000000 0x00000000
					0x001112a0 0x00000000 0x0003033d 0x00000000
					0x77ffc084 0x81f1f108 0x03035504 0x00000000
					0x0000003f 0x00000000 0x02000000 0x00000802
					0x00020000 0x00000100 0x0158000c 0x0158000c
					0x07070707 0x00000404 0x00000000 0x00000000
					0x80001944 0x1f7df7df 0x0000001f 0x02000006
					0x80000190 0x00000001 0x00000002 0x0000000a
					0x00000006 0x00000008 0x00000001 0x00000002
					0x00000009 0x00000002 0x00000002 0x00000004
					0x00000006 0x06040202 0x000e070a 0x7547130b
					0x001f0000>;
				nvidia,emc-trimmers-0 = <0x00000000 0x00000006
					0x00000007 0x00000005 0x00000004 0x00030000
					0x0000000c 0x00000000 0x0000000e 0x0079e79e
					0x20820800 0x00018000 0xa0f10000 0x00008000
					0x00000000 0x00000000 0x00008000 0x00008000
					0x00030000 0x00030000 0x00030000 0x00018000
					0x00018000 0x00018000 0x00000000 0x00000000
					0x00000000 0x00000000 0x00000000 0x00000000>;
				nvidia,emc-trimmers-1 = <0x00000000 0x00000006
					0x00000007 0x00000005 0x00000004 0x00030000
					0x0000000c 0x00000000 0x0000000e 0x0079e79e
					0x20820800 0x00018000 0xa8f10000 0x00008000
					0x00000000 0x00000000 0x00008000 0x00008000
					0x00030000 0x00030000 0x00030000 0x00018000
					0x00018000 0x00018000 0x00000000 0x00000000
					0x00000000 0x00000000 0x00000000 0x00000000>;
				nvidia,emc-burst-up-down-regs = <0x000000d1 0x00110011
					0x00110013 0x00150017 0x00000017 0x00170017
					0x001f0017 0x0000001f 0x001f001f 0x00d30064
					0x00d300d3>;
				nvidia,emc-zcal-cnt-long = <0x00000042>;
				nvidia,emc-acal-interval = <0x001fffff>;
				nvidia,emc-cfg = <0x73200006>;
				nvidia,emc-mode-reset = <0x80000731>;
				nvidia,emc-mode-1 = <0x80100002>;
				nvidia,emc-mode-2 = <0x80200008>;
				nvidia,emc-mode-4 = <0x00000000>;
				nvidia,emc-clock-latency-change = <1750>;
			};
			emc-table@480000 {
				compatible = "nvidia,tegra11-emc-table";
				clock-frequency = <480000>;
				nvidia,revision = <0x41>;
				nvidia,src-sel-reg = <0x80000000>;
				nvidia,emc-min-mv = <1100>;
				nvidia,burst-regs-num = <99>;
				nvidia,emc-trimmers-num = <30>;
				nvidia,burst-up-down-regs-num = <11>;
				nvidia,emc-registers = <0x00000017 0x00000082
					0x00000000 0x00000010 0x00000005 0x00000005
					0x00000009 0x00000002 0x0000000d 0x00000005
					0x00000005 0x00000002 0x00000001 0x00000000
					0x00000004 0x00000004 0x00000007 0x00010000
					0x00000000 0x00000004 0x0000000e 0x00000f23
					0x00000000 0x000003c8 0x00000002 0x0000000b
					0x00000001 0x00000000 0x0000007f 0x00000012
					0x00000089 0x00000200 0x00000004 0x00000004
					0x00000004 0x00000015 0x00000000 0x00000005
					0x00000006 0x00000f64 0x00000006 0x00000020
					0x00000000 0x0000ba88 0xf0140091 0x00008000
					0x0000000a 0x0000000a 0x0000000a 0x0000000a
					0x00000000 0x00000000 0x00000000 0x00000000
					0x00000000 0x00000000 0x00000000 0x00000000
					0x001112a0 0x00000000 0x0003033d 0x00000000
					0x77ffc084 0x81f1f108 0x07077704 0x00000000
					0x0000003f 0x00000000 0x02000000 0x00000802
					0x00020000 0x00000100 0x013f000c 0x013f000c
					0x00000000 0x00000808 0x00000000 0x00000000
					0x80001f05 0x1f7df7df 0x0000001f 0x09000007
					0x80000190 0x00000002 0x00000003 0x0000000c
					0x00000007 0x0000000a 0x00000001 0x00000002
					0x00000009 0x00000002 0x00000002 0x00000004
					0x00000006 0x06040202 0x000f080c 0x7448170d
					0x001f0000>;
				nvidia,emc-trimmers-0 = <0x00000000 0x00000006
					0x00000007 0x00000005 0x00000006 0x0000000a
					0x0000000c 0x00000000 0x0000000e 0x0079e79e
					0x20820800 0x0000400b 0xa0f10f0f 0x00000000
					0x00000000 0x00000000 0x00000000 0x00000000
					0x0000000a 0x0000000a 0x0000000a 0x0000000c
					0x0000000c 0x0000400b 0x00000000 0x00000000
					0x00000000 0x00000000 0x00000000 0x00000000>;
				nvidia,emc-trimmers-1 = <0x00000000 0x00000006
					0x00000007 0x00000005 0x00000006 0x0000000a
					0x0000000c 0x00000000 0x0000000e 0x0079e79e
					0x20820800 0x0000400b 0xa8f10f0f 0x00000000
					0x00000000 0x00000000 0x00000000 0x00000000
					0x0000000a 0x0000000a 0x0000000a 0x0000000c
					0x0000000c 0x0000400b 0x00000000 0x00000000
					0x00000000 0x00000000 0x00000000 0x00000000>;
				nvidia,emc-burst-up-down-regs = <0x000000f6 0x000f000f
					0x000f0010 0x00120014 0x00000014 0x00140014
					0x001a0014 0x0000001a 0x001a001a 0x00b40055
					0x00b400b4>;
				nvidia,emc-zcal-cnt-long = <0x00000042>;
				nvidia,emc-acal-interval = <0x001fffff>;
				nvidia,emc-cfg = <0x73200006>;
				nvidia,emc-mode-reset = <0x80000931>;
				nvidia,emc-mode-1 = <0x80100002>;
				nvidia,emc-mode-2 = <0x80200008>;
				nvidia,emc-mode-4 = <0x00000000>;
				nvidia,emc-clock-latency-change = <1750>;
			};
		};
	};

	backlight {
		compatible = "pwm-backlight";
		pwms = <&pwm 1 5000000>;
		brightness-levels = <0 4 8 16 32 64 128 255>;
		default-brightness-level = <6>;
		enable-supply = <&lcd_bl_en_reg>;
	};

	gpio-keys {
		compatible = "gpio-keys";

		home {
			label = "Home";
			gpios = <&gpio 69 1>; /* gpio PI5, active low */
			linux,code = <102>; /* KEY_HOME */
		};

		power {
			label = "Power";
			gpios = <&gpio 128 1>; /* gpio PQ0, active low */
			linux,code = <116>; /* KEY_POWER */
			gpio-key,wakeup;
		};

		volume_down {
			label = "Volume Down";
			gpios = <&gpio 137 1>; /* gpio PR1, active low */
			linux,code = <114>; /* KEY_VOLUMEDOWN */
		};

		volume_up {
			label = "Volume Up";
			gpios = <&gpio 138 1>; /* gpio PR2, active low */
			linux,code = <115>; /* KEY_VOLUMEUP */
		};
	};

	regulators {
		compatible = "simple-bus";
		#address-cells = <1>;
		#size-cells = <0>;

		vdd_ac_bat_reg: regulator@0 {
			compatible = "regulator-fixed";
			reg = <0>;
			regulator-name = "vdd_ac_bat";
			regulator-min-microvolt = <5000000>;
			regulator-max-microvolt = <5000000>;
			regulator-always-on;
		};

		dvdd_ts_reg: regulator@1 {
			compatible = "regulator-fixed";
			reg = <1>;
			regulator-name = "dvdd_ts";
			regulator-min-microvolt = <1800000>;
			regulator-max-microvolt = <1800000>;
			enable-active-high;
			gpio = <&gpio TEGRA_GPIO(H, 5) GPIO_ACTIVE_HIGH>;
		};

		lcd_bl_en_reg: regulator@2 {
			compatible = "regulator-fixed";
			reg = <2>;
			regulator-name = "lcd_bl_en";
			regulator-min-microvolt = <5000000>;
			regulator-max-microvolt = <5000000>;
			enable-active-high;
			regulator-boot-on;
			gpio = <&gpio TEGRA_GPIO(H, 2) GPIO_ACTIVE_HIGH>;
		};

		usb1_vbus_reg: regulator@3 {
			compatible = "regulator-fixed";
			reg = <3>;
			regulator-name = "usb1_vbus";
			regulator-min-microvolt = <5000000>;
			regulator-max-microvolt = <5000000>;
			enable-active-high;
			gpio = <&gpio TEGRA_GPIO(N, 4) GPIO_ACTIVE_HIGH>;
			gpio-open-drain;
			vin-supply = <&tps65090_dcdc1_reg>;
		};

		usb3_vbus_reg: regulator@4 {
			compatible = "regulator-fixed";
			reg = <4>;
			regulator-name = "usb2_vbus";
			regulator-min-microvolt = <5000000>;
			regulator-max-microvolt = <5000000>;
			enable-active-high;
			gpio = <&gpio TEGRA_GPIO(K, 6) GPIO_ACTIVE_HIGH>;
			gpio-open-drain;
			vin-supply = <&tps65090_dcdc1_reg>;
		};

		vdd_hdmi_reg: regulator@5 {
			compatible = "regulator-fixed";
			reg = <5>;
			regulator-name = "vdd_hdmi_5v0";
			regulator-min-microvolt = <5000000>;
			regulator-max-microvolt = <5000000>;
			enable-active-high;
			gpio = <&gpio TEGRA_GPIO(K, 1) GPIO_ACTIVE_HIGH>;
			vin-supply = <&tps65090_dcdc1_reg>;
		};

		vdd_cam_1v8_reg: regulator@6 {
			compatible = "regulator-fixed";
			reg = <6>;
			regulator-name = "vdd_cam_1v8_reg";
			regulator-min-microvolt = <1800000>;
			regulator-max-microvolt = <1800000>;
			enable-active-high;
			gpio = <&palmas_gpio 6 0>;
		};
	};
};
